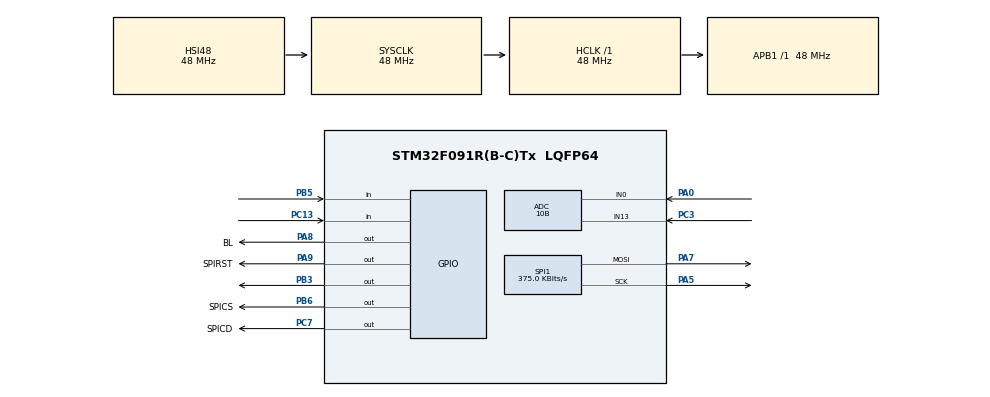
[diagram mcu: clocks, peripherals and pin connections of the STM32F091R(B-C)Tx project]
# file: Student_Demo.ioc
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ADC.ClockPrescaler=ADC_CLOCK_ASYNC_DIV1
ADC.ContinuousConvMode=DISABLE
ADC.Resolution=ADC_RESOLUTION_10B
Mcu.Family=STM32F0
Mcu.Name=STM32F091R(B-C)Tx
Mcu.Package=LQFP64
PA0.Signal=SharedAnalog_PA0
PA5.Mode=TX_Only_Simplex_Unidirect_Master
PA5.Signal=SPI1_SCK
PA7.Mode=TX_Only_Simplex_Unidirect_Master
PA7.Signal=SPI1_MOSI
PA8.GPIO_Label=BL
PA8.Signal=GPIO_Output
PA9.GPIO_Label=SPIRST
PA9.Signal=GPIO_Output
PB3.Signal=GPIO_Output
PB5.Signal=GPIO_Input
PB6.GPIO_Label=SPICS
PB6.Signal=GPIO_Output
PC13.Signal=GPIO_Input
PC14OSC32_IN.Mode=LSE-External-Oscillator
PC14OSC32_IN.Signal=RCC_OSC32_IN
PC15OSC32_OUT.Mode=LSE-External-Oscillator
PC15OSC32_OUT.Signal=RCC_OSC32_OUT
PC3.Mode=IN13
PC3.Signal=ADC_IN13
PC7.GPIO_Label=SPICD
PC7.PinState=GPIO_PIN_SET
PC7.Signal=GPIO_Output
PF0-OSC_IN.Mode=HSE-External-Oscillator
PF0-OSC_IN.Signal=RCC_OSC_IN
PF1-OSC_OUT.Mode=HSE-External-Oscillator
PF1-OSC_OUT.Signal=RCC_OSC_OUT
ProjectManager.HeapSize=0x200
ProjectManager.StackSize=0x400
ProjectManager.TargetToolchain=STM32CubeIDE
RCC.AHBFreq_Value=48000000
RCC.APB1Freq_Value=48000000
RCC.APB1TimFreq_Value=48000000
RCC.FLatency-AdvancedSettings=FLASH_LATENCY_1
RCC.HCLKFreq_Value=48000000
RCC.PLLDivider=RCC_PREDIV_DIV2
RCC.PLLMUL=RCC_PLL_MUL12
RCC.PLLSourceVirtual=RCC_PLLSOURCE_HSE
RCC.PREFETCH_ENABLE-AdvancedSettings=1
RCC.SYSCLKFreq_VALUE=48000000
RCC.SYSCLKSource=RCC_SYSCLKSOURCE_HSI48
SH.SharedAnalog_PA0.0=GPIO_Analog
SH.SharedAnalog_PA0.1=ADC_IN0,IN0
SPI1.BaudRatePrescaler=SPI_BAUDRATEPRESCALER_128
SPI1.CalculateBaudRate=375.0 KBits/s
SPI1.DataSize=SPI_DATASIZE_8BIT
SPI1.Direction=SPI_DIRECTION_2LINES
SPI1.Mode=SPI_MODE_MASTER
SPI1.VirtualType=VM_MASTER
TIM16.Period=10000
TIM16.Prescaler=4800-1
VP_ADC_TempSens_Input.Mode=IN-TempSens
VP_ADC_Vbat_Input.Mode=IN-Vbat
VP_TIM16_VS_ClockSourceINT.Mode=Enable_Timer
board=NUCLEO-F091RC

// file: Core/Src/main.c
/* USER CODE BEGIN Header */
/**
 ******************************************************************************
 * @file           : main.c
 * @brief          : Main program body
 ******************************************************************************
 * @attention
 *
 * Copyright (c) 2022 STMicroelectronics.
 * All rights reserved.
 *
 * This software is licensed under terms that can be found in the LICENSE file
 * in the root directory of this software component.
 * If no LICENSE file comes with this software, it is provided AS-IS.
 *
 ******************************************************************************
 */
/* USER CODE END Header */
#include "main.h"

/* USER CODE BEGIN Includes */
#include "OS.h"
#include "lcd_st7565_pinconf.h"
#include "lcd_st7565.h"
#include "font.h"

#define Avg_Slope .0025
#define V25 0.76
float val = 0.0;
double Temp = 0.0;
#define ItemiMeniu 6

/* USER CODE END Includes */

ADC_HandleTypeDef hadc;

SPI_HandleTypeDef hspi1;

TIM_HandleTypeDef htim16;

void SystemClock_Config(void);
static void MX_GPIO_Init(void);
static void MX_TIM16_Init(void);
static void MX_ADC_Init(void);
static void MX_SPI1_Init(void);
/* USER CODE BEGIN PFP */
void ADC_Select_CH0 (int rang);
void ADC_Select_CH13 (int rang);
void ADC_Disable_CH13(void);
void ADC_Disable_CH0(void);
void ADC_Disable_CHtemp(void);
void ADC_Select_CHTemp (int rang);
/* USER CODE END PFP */

/* USER CODE BEGIN 0 */
uint8_t ptData[] =
{ // 'j_b-removebg-1200x1200', 128x64px
		0x00, 0x00, 0x00, 0x00, 0x00, 0x00, 0x00, 0x00, 0x00, 0x00, 0x00, 0x00, 0x00, 0x00, 0x00, 0x00,
			0x00, 0x00, 0x00, 0x00, 0x00, 0x00, 0x00, 0x00, 0x00, 0x00, 0x00, 0x00, 0x00, 0x00, 0x00, 0x00,
			0x00, 0x00, 0x00, 0x00, 0x00, 0x00, 0x00, 0x00, 0x00, 0x00, 0x00, 0x00, 0x00, 0x00, 0x00, 0x00,
			0x00, 0x00, 0x00, 0x00, 0x00, 0x00, 0x00, 0x00, 0x00, 0x00, 0x00, 0x00, 0x00, 0x00, 0x00, 0x00,
			0x00, 0x00, 0x00, 0x00, 0x00, 0x00, 0x00, 0x00, 0x00, 0x00, 0x00, 0x00, 0x00, 0x00, 0x00, 0x00,
			0x00, 0x00, 0x00, 0x00, 0x00, 0x00, 0x00, 0x00, 0x00, 0x00, 0x00, 0x00, 0x00, 0x00, 0x00, 0x00,
			0x00, 0x00, 0x00, 0x00, 0x00, 0x00, 0x00, 0x00, 0x00, 0x80, 0xc0, 0xc0, 0xc0, 0xc0, 0xf0, 0xf0,
			0xf0, 0xf0, 0xf0, 0xf0, 0xf0, 0xf0, 0xc0, 0xc0, 0xc0, 0xc0, 0x80, 0x00, 0x00, 0x00, 0x00, 0x00,
			0x00, 0x00, 0x00, 0x00, 0x00, 0x00, 0x00, 0x00, 0x00, 0x00, 0x00, 0x00, 0x00, 0x00, 0x00, 0x00,
			0x00, 0x00, 0x00, 0x00, 0x00, 0x00, 0x00, 0x00, 0x00, 0x00, 0x00, 0x00, 0x00, 0x00, 0x00, 0x00,
			0x00, 0x00, 0x00, 0x00, 0x00, 0x00, 0x00, 0x00, 0x00, 0x00, 0x00, 0x00, 0x00, 0x00, 0x00, 0x00,
			0x00, 0x00, 0x00, 0x00, 0x00, 0x00, 0x00, 0x00, 0x00, 0x00, 0x00, 0x00, 0x00, 0x00, 0x00, 0x00,
			0x00, 0x00, 0x00, 0x00, 0x00, 0x00, 0x00, 0x00, 0x00, 0x00, 0x00, 0x00, 0x00, 0x00, 0x00, 0x00,
			0x00, 0x00, 0x00, 0x00, 0x00, 0x00, 0x00, 0x00, 0x00, 0x00, 0x00, 0x00, 0x00, 0x00, 0x00, 0x00,
			0x00, 0x00, 0x00, 0x00, 0x00, 0x00, 0x00, 0x00, 0x00, 0xff, 0x00, 0x00, 0x00, 0x00, 0x00, 0x00,
			0x00, 0x00, 0x00, 0x00, 0x00, 0x00, 0x00, 0x00, 0x00, 0x00, 0xff, 0x00, 0x00, 0x00, 0x00, 0x00,
			0x00, 0x00, 0x00, 0x00, 0x00, 0x00, 0x00, 0x00, 0x00, 0x00, 0x00, 0x00, 0x00, 0x00, 0x00, 0x00,
			0x00, 0x00, 0x00, 0x00, 0x00, 0x00, 0x00, 0x00, 0x00, 0x00, 0x00, 0x00, 0x00, 0x00, 0x00, 0x00,
			0x00, 0x00, 0x00, 0x00, 0x00, 0x00, 0x00, 0x00, 0x00, 0x00, 0x00, 0x00, 0x00, 0x00, 0x00, 0x00,
			0x00, 0x00, 0x00, 0x00, 0x00, 0x00, 0x00, 0x00, 0x00, 0x00, 0x00, 0x00, 0x00, 0x00, 0x00, 0x00,
			0x00, 0x00, 0x00, 0x00, 0x00, 0x00, 0x00, 0x00, 0x00, 0x00, 0x00, 0x00, 0x00, 0x00, 0x00, 0x00,
			0x00, 0x00, 0x00, 0x00, 0x00, 0x00, 0x00, 0x00, 0x00, 0x00, 0x00, 0x00, 0x00, 0x00, 0x00, 0x00,
			0x00, 0x00, 0x00, 0x00, 0x00, 0x00, 0x00, 0x00, 0x00, 0xff, 0x00, 0x00, 0x00, 0x00, 0x00, 0x00,
			0x00, 0x00, 0x00, 0x00, 0x00, 0x00, 0x00, 0x00, 0x00, 0x00, 0xff, 0x00, 0x00, 0x00, 0x00, 0x00,
			0x00, 0x00, 0x00, 0x00, 0x00, 0x00, 0x00, 0x00, 0x00, 0x00, 0x00, 0x00, 0x00, 0x00, 0x00, 0x00,
			0x00, 0x00, 0x00, 0x00, 0x00, 0x00, 0x00, 0x00, 0x00, 0x00, 0x00, 0x00, 0x00, 0x00, 0x00, 0x00,
			0x00, 0x00, 0x00, 0x00, 0x00, 0x00, 0x00, 0x00, 0x00, 0x00, 0x00, 0x00, 0x00, 0x00, 0x00, 0x00,
			0x00, 0x00, 0x00, 0x00, 0x00, 0x00, 0x00, 0x00, 0x00, 0x00, 0x00, 0x00, 0x00, 0x00, 0x00, 0x00,
			0x00, 0x00, 0x00, 0x00, 0x00, 0x00, 0x00, 0x00, 0x00, 0x00, 0x00, 0x00, 0x00, 0x00, 0x00, 0x00,
			0x00, 0x00, 0x00, 0x00, 0x00, 0x00, 0x00, 0x00, 0x00, 0x00, 0x00, 0x00, 0x00, 0x00, 0x00, 0x00,
			0x00, 0x00, 0x00, 0x00, 0x00, 0x00, 0x00, 0x00, 0x00, 0xff, 0x00, 0x00, 0x00, 0x00, 0x00, 0x00,
			0x00, 0x00, 0x00, 0x00, 0x00, 0x00, 0x00, 0x00, 0x00, 0x00, 0xff, 0x00, 0x00, 0x00, 0x00, 0x00,
			0x00, 0x00, 0x00, 0x00, 0x00, 0x00, 0x00, 0x00, 0x00, 0x00, 0x00, 0x00, 0x00, 0x00, 0x00, 0x00,
			0x00, 0x00, 0x00, 0x00, 0x00, 0x00, 0x00, 0x00, 0x00, 0x00, 0x00, 0x00, 0x00, 0x00, 0x00, 0x00,
			0x00, 0x00, 0x00, 0x00, 0x00, 0x00, 0x00, 0x00, 0x00, 0x00, 0x00, 0x00, 0x00, 0x00, 0x00, 0x00,
			0x00, 0x00, 0x00, 0x00, 0x00, 0x00, 0x00, 0x00, 0x00, 0x00, 0x00, 0x00, 0x00, 0x00, 0x00, 0x00,
			0x00, 0x00, 0x00, 0x00, 0x00, 0x00, 0x00, 0x00, 0x00, 0x00, 0x00, 0x00, 0x00, 0x00, 0x00, 0x00,
			0x00, 0x00, 0x00, 0x00, 0x00, 0x00, 0x00, 0x00, 0x00, 0x00, 0x00, 0x00, 0x00, 0x00, 0x00, 0x00,
			0x00, 0x00, 0x00, 0x00, 0x00, 0x00, 0x00, 0x00, 0x00, 0xff, 0x00, 0x00, 0x00, 0x00, 0x00, 0x00,
			0x00, 0x00, 0x00, 0x00, 0x00, 0x00, 0x00, 0x00, 0x00, 0x00, 0xff, 0x00, 0x00, 0x00, 0x00, 0x00,
			0x00, 0x00, 0x00, 0x00, 0x00, 0x00, 0x00, 0x00, 0x00, 0x00, 0x00, 0x00, 0x00, 0x00, 0x00, 0x00,
			0x00, 0x00, 0x00, 0x00, 0x00, 0x00, 0x00, 0x00, 0x00, 0x00, 0x00, 0x00, 0x00, 0x00, 0x00, 0x00,
			0x00, 0x00, 0x00, 0x00, 0x00, 0x00, 0x00, 0x00, 0x00, 0x00, 0x00, 0x00, 0x00, 0x00, 0x00, 0x00,
			0x00, 0x00, 0x00, 0x00, 0x00, 0x00, 0x00, 0x00, 0x00, 0x00, 0x00, 0x00, 0x00, 0x00, 0x00, 0x00,
			0x00, 0x00, 0x00, 0x00, 0x00, 0x00, 0x00, 0x00, 0x00, 0x00, 0x00, 0x00, 0x00, 0x00, 0x00, 0x00,
			0x00, 0x00, 0x00, 0x00, 0x00, 0x00, 0x00, 0x00, 0x00, 0x00, 0x00, 0x00, 0x00, 0x00, 0x00, 0x00,
			0x00, 0x00, 0x00, 0x00, 0x00, 0x00, 0x00, 0x00, 0x00, 0xff, 0x00, 0x00, 0x00, 0x00, 0x00, 0x00,
			0x00, 0x00, 0x00, 0x00, 0x00, 0x00, 0x00, 0x00, 0x00, 0x00, 0xff, 0x00, 0x00, 0x00, 0x00, 0x00,
			0x00, 0x00, 0x00, 0x00, 0x00, 0x00, 0x00, 0x00, 0x00, 0x00, 0x00, 0x00, 0x00, 0x00, 0x00, 0x00,
			0x00, 0x00, 0x00, 0x00, 0x00, 0x00, 0x00, 0x00, 0x00, 0x00, 0x00, 0x00, 0x00, 0x00, 0x00, 0x00,
			0x00, 0x00, 0x00, 0x00, 0x00, 0x00, 0x00, 0x00, 0x00, 0x00, 0x00, 0x00, 0x00, 0x00, 0x00, 0x00,
			0x00, 0x00, 0x00, 0x00, 0x00, 0x00, 0x00, 0x00, 0x00, 0x00, 0x00, 0x00, 0x00, 0x00, 0x00, 0x00,
			0x00, 0x00, 0x00, 0x00, 0x00, 0x00, 0x00, 0x00, 0x00, 0x00, 0x00, 0x00, 0x00, 0x00, 0x00, 0x00,
			0x00, 0x00, 0x00, 0x00, 0x00, 0x00, 0x00, 0x00, 0x00, 0x00, 0x00, 0x00, 0x00, 0x00, 0x00, 0x00,
			0x00, 0x00, 0x00, 0x00, 0x00, 0x00, 0x00, 0x00, 0x00, 0xff, 0x00, 0x00, 0x00, 0x00, 0x00, 0x00,
			0x00, 0x00, 0x00, 0x00, 0x00, 0x00, 0x00, 0x00, 0x00, 0x00, 0xff, 0x00, 0x00, 0x00, 0x00, 0x00,
			0x00, 0x00, 0x00, 0x00, 0x00, 0x00, 0x00, 0x00, 0x00, 0x00, 0x00, 0x00, 0x00, 0x00, 0x00, 0x00,
			0x00, 0x00, 0x00, 0x00, 0x00, 0x00, 0x00, 0x00, 0x00, 0x00, 0x00, 0x00, 0x00, 0x00, 0x00, 0x00,
			0x00, 0x00, 0x00, 0x00, 0x00, 0x00, 0x00, 0x00, 0x00, 0x00, 0x00, 0x00, 0x00, 0x00, 0x00, 0x00,
			0x00, 0x00, 0x00, 0x00, 0x00, 0x00, 0x00, 0x00, 0x00, 0x00, 0x00, 0x00, 0x00, 0x00, 0x00, 0x00,
			0x00, 0x00, 0x00, 0x00, 0x00, 0x00, 0x00, 0x00, 0x00, 0x00, 0x00, 0x00, 0x00, 0x00, 0x00, 0x00,
			0x00, 0x00, 0x00, 0x00, 0x00, 0x00, 0x00, 0x00, 0x00, 0x00, 0x00, 0x00, 0x00, 0x00, 0x00, 0x00,
			0x00, 0x00, 0x00, 0x00, 0x00, 0x00, 0x00, 0x00, 0x00, 0x07, 0x06, 0x0e, 0x0e, 0x0e, 0x0e, 0x0e,
			0x0e, 0x0e, 0x0e, 0x0e, 0x0e, 0x0e, 0x0e, 0x0e, 0x0e, 0x0e, 0x07, 0x00, 0x00, 0x00, 0x00, 0x00};

uint8_t ptData1[] =
{ // 'j_b-removebg-1200x1200', 128x64px
		0x00, 0x00, 0x00, 0x00, 0x00, 0x00, 0x00, 0x00, 0x00, 0x00, 0x00, 0x00, 0x00, 0x00, 0x00, 0x00,
		0x00, 0x00, 0x00, 0x00, 0x00, 0x00, 0x00, 0x00, 0x00, 0x00, 0x00, 0x00, 0x00, 0x00, 0x00, 0x00,
		0x00, 0x00, 0x00, 0x00, 0x00, 0x00, 0x00, 0x00, 0x00, 0x00, 0x00, 0x00, 0x00, 0x00, 0x00, 0x00,
		0x00, 0x00, 0x00, 0x00, 0x00, 0x00, 0x00, 0x00, 0x00, 0x00, 0x00, 0x00, 0x00, 0x00, 0x00, 0x00,
		0x00, 0x00, 0x00, 0x00, 0x00, 0x00, 0x00, 0x00, 0x00, 0x00, 0x00, 0x00, 0x00, 0x00, 0x00, 0x00,
		0x00, 0x00, 0x00, 0x00, 0x00, 0x00, 0x00, 0x00, 0x00, 0x00, 0x00, 0x00, 0x00, 0x00, 0x00, 0x00,
		0x00, 0x00, 0x00, 0x00, 0x00, 0x00, 0x00, 0x00, 0x00, 0x00, 0x80, 0xc0, 0xc0, 0xc0, 0xc0, 0xf0,
		0xf0, 0xf0, 0xf0, 0xf0, 0xf0, 0xf0, 0xf0, 0xc0, 0xc0, 0xc0, 0xc0, 0x80, 0x00, 0x00, 0x00, 0x00,
		0x00, 0x00, 0x00, 0x00, 0x00, 0x00, 0x00, 0x00, 0x00, 0x00, 0x00, 0x00, 0x00, 0x00, 0x00, 0x00,
		0x00, 0x00, 0x00, 0x00, 0x00, 0x00, 0x00, 0x00, 0x00, 0x00, 0x00, 0x00, 0x00, 0x00, 0x00, 0x00,
		0x00, 0x00, 0x00, 0x00, 0x00, 0x00, 0x00, 0x00, 0x00, 0x00, 0x00, 0x00, 0x00, 0x00, 0x00, 0x00,
		0x00, 0x00, 0x00, 0x00, 0x00, 0x00, 0x00, 0x00, 0x00, 0x00, 0x00, 0x00, 0x00, 0x00, 0x00, 0x00,
		0x00, 0x00, 0x00, 0x00, 0x00, 0x00, 0x00, 0x00, 0x00, 0x00, 0x00, 0x00, 0x00, 0x00, 0x00, 0x00,
		0x00, 0x00, 0x00, 0x00, 0x00, 0x00, 0x00, 0x00, 0x00, 0x00, 0x00, 0x00, 0x00, 0x00, 0x00, 0x00,
		0x00, 0x00, 0x00, 0x00, 0x00, 0x00, 0x00, 0x00, 0x00, 0x00, 0xff, 0x00, 0x00, 0x00, 0x00, 0x00,
		0x00, 0x00, 0x00, 0x00, 0x00, 0x00, 0x00, 0x00, 0x00, 0x00, 0x00, 0xff, 0x00, 0x00, 0x00, 0x00,
		0x00, 0x00, 0x00, 0x00, 0x00, 0x00, 0x00, 0x00, 0x00, 0x00, 0x00, 0x00, 0x00, 0x00, 0x00, 0x00,
		0x00, 0x00, 0x00, 0x00, 0x00, 0x00, 0x00, 0x00, 0x00, 0x00, 0x00, 0x00, 0x00, 0x00, 0x00, 0x00,
		0x00, 0x00, 0x00, 0x00, 0x00, 0x00, 0x00, 0x00, 0x00, 0x00, 0x00, 0x00, 0x00, 0x00, 0x00, 0x00,
		0x00, 0x00, 0x00, 0x00, 0x00, 0x00, 0x00, 0x00, 0x00, 0x00, 0x00, 0x00, 0x00, 0x00, 0x00, 0x00,
		0x00, 0x00, 0x00, 0x00, 0x00, 0x00, 0x00, 0x00, 0x00, 0x00, 0x00, 0x00, 0x00, 0x00, 0x00, 0x00,
		0x00, 0x00, 0x00, 0x00, 0x00, 0x00, 0x00, 0x00, 0x00, 0x00, 0x00, 0x00, 0x00, 0x00, 0x00, 0x00,
		0x00, 0x00, 0x00, 0x00, 0x00, 0x00, 0x00, 0x00, 0x00, 0x00, 0xff, 0x00, 0x00, 0x00, 0x00, 0x00,
		0x00, 0x00, 0x00, 0x00, 0x00, 0x00, 0x00, 0x00, 0x00, 0x00, 0x00, 0xff, 0x00, 0x00, 0x00, 0x00,
		0x00, 0x00, 0x00, 0x00, 0x00, 0x00, 0x00, 0x00, 0x00, 0x00, 0x00, 0x00, 0x00, 0x00, 0x00, 0x00,
		0x00, 0x00, 0x00, 0x00, 0x00, 0x00, 0x00, 0x00, 0x00, 0x00, 0x00, 0x00, 0x00, 0x00, 0x00, 0x00,
		0x00, 0x00, 0x00, 0x00, 0x00, 0x00, 0x00, 0x00, 0x00, 0x00, 0x00, 0x00, 0x00, 0x00, 0x00, 0x00,
		0x00, 0x00, 0x00, 0x00, 0x00, 0x00, 0x00, 0x00, 0x00, 0x00, 0x00, 0x00, 0x00, 0x00, 0x00, 0x00,
		0x00, 0x00, 0x00, 0x00, 0x00, 0x00, 0x00, 0x00, 0x00, 0x00, 0x00, 0x00, 0x00, 0x00, 0x00, 0x00,
		0x00, 0x00, 0x00, 0x00, 0x00, 0x00, 0x00, 0x00, 0x00, 0x00, 0x00, 0x00, 0x00, 0x00, 0x00, 0x00,
		0x00, 0x00, 0x00, 0x00, 0x00, 0x00, 0x00, 0x00, 0x00, 0x00, 0xff, 0x00, 0x00, 0x00, 0x00, 0x00,
		0x00, 0x00, 0x00, 0x00, 0x00, 0x00, 0x00, 0x00, 0x00, 0x00, 0x00, 0xff, 0x00, 0x00, 0x00, 0x00,
		0x00, 0x00, 0x00, 0x00, 0x00, 0x00, 0x00, 0x00, 0x00, 0x00, 0x00, 0x00, 0x00, 0x00, 0x00, 0x00,
		0x00, 0x00, 0x00, 0x00, 0x00, 0x00, 0x00, 0x00, 0x00, 0x00, 0x00, 0x00, 0x00, 0x00, 0x00, 0x00,
		0x00, 0x00, 0x00, 0x00, 0x00, 0x00, 0x00, 0x00, 0x00, 0x00, 0x00, 0x00, 0x00, 0x00, 0x00, 0x00,
		0x00, 0x00, 0x00, 0x00, 0x00, 0x00, 0x00, 0x00, 0x00, 0x00, 0x00, 0x00, 0x00, 0x00, 0x00, 0x00,
		0x00, 0x00, 0x00, 0x00, 0x00, 0x00, 0x00, 0x00, 0x00, 0x00, 0x00, 0x00, 0x00, 0x00, 0x00, 0x00,
		0x00, 0x00, 0x00, 0x00, 0x00, 0x00, 0x00, 0x00, 0x00, 0x00, 0x00, 0x00, 0x00, 0x00, 0x00, 0x00,
		0x00, 0x00, 0x00, 0x00, 0x00, 0x00, 0x00, 0x00, 0x00, 0x00, 0xff, 0x00, 0x00, 0x00, 0x00, 0x00,
		0x00, 0x00, 0x00, 0x00, 0x00, 0x00, 0x00, 0x00, 0x00, 0x00, 0x00, 0xff, 0x00, 0x00, 0x00, 0x00,
		0x00, 0x00, 0x00, 0x00, 0x00, 0x00, 0x00, 0x00, 0x00, 0x00, 0x00, 0x00, 0x00, 0x00, 0x00, 0x00,
		0x00, 0x00, 0x00, 0x00, 0x00, 0x00, 0x00, 0x00, 0x00, 0x00, 0x00, 0x00, 0x00, 0x00, 0x00, 0x00,
		0x00, 0x00, 0x00, 0x00, 0x00, 0x00, 0x00, 0x00, 0x00, 0x00, 0x00, 0x00, 0x00, 0x00, 0x00, 0x00,
		0x00, 0x00, 0x00, 0x00, 0x00, 0x00, 0x00, 0x00, 0x00, 0x00, 0x00, 0x00, 0x00, 0x00, 0x00, 0x00,
		0x00, 0x00, 0x00, 0x00, 0x00, 0x00, 0x00, 0x00, 0x00, 0x00, 0x00, 0x00, 0x00, 0x00, 0x00, 0x00,
		0x00, 0x00, 0x00, 0x00, 0x00, 0x00, 0x00, 0x00, 0x00, 0x00, 0x00, 0x00, 0x00, 0x00, 0x00, 0x00,
		0x00, 0x00, 0x00, 0x00, 0x00, 0x00, 0x00, 0x00, 0x00, 0x00, 0xff, 0x00, 0x00, 0x00, 0x00, 0x00,
		0x00, 0x00, 0x00, 0x00, 0x00, 0x00, 0x00, 0x00, 0x00, 0x00, 0x00, 0xff, 0x00, 0x00, 0x00, 0x00,
		0x00, 0x00, 0x00, 0x00, 0x00, 0x00, 0x00, 0x00, 0x00, 0x00, 0x00, 0x00, 0x00, 0x00, 0x00, 0x00,
		0x00, 0x00, 0x00, 0x00, 0x00, 0x00, 0x00, 0x00, 0x00, 0x00, 0x00, 0x00, 0x00, 0x00, 0x00, 0x00,
		0x00, 0x00, 0x00, 0x00, 0x00, 0x00, 0x00, 0x00, 0x00, 0x00, 0x00, 0x00, 0x00, 0x00, 0x00, 0x00,
		0x00, 0x00, 0x00, 0x00, 0x00, 0x00, 0x00, 0x00, 0x00, 0x00, 0x00, 0x00, 0x00, 0x00, 0x00, 0x00,
		0x00, 0x00, 0x00, 0x00, 0x00, 0x00, 0x00, 0x00, 0x00, 0x00, 0x00, 0x00, 0x00, 0x00, 0x00, 0x00,
		0x00, 0x00, 0x00, 0x00, 0x00, 0x00, 0x00, 0x00, 0x00, 0x00, 0x00, 0x00, 0x00, 0x00, 0x00, 0x00,
		0x00, 0x00, 0x00, 0x00, 0x00, 0x00, 0x00, 0x00, 0x00, 0x00, 0xff, 0x00, 0x7f, 0x7f, 0x7f, 0x7f,
		0x7f, 0x7f, 0x7f, 0x7f, 0x7f, 0x7f, 0x7f, 0x7f, 0x7f, 0x00, 0x00, 0xff, 0x00, 0x00, 0x00, 0x00,
		0x00, 0x00, 0x00, 0x00, 0x00, 0x00, 0x00, 0x00, 0x00, 0x00, 0x00, 0x00, 0x00, 0x00, 0x00, 0x00,
		0x00, 0x00, 0x00, 0x00, 0x00, 0x00, 0x00, 0x00, 0x00, 0x00, 0x00, 0x00, 0x00, 0x00, 0x00, 0x00,
		0x00, 0x00, 0x00, 0x00, 0x00, 0x00, 0x00, 0x00, 0x00, 0x00, 0x00, 0x00, 0x00, 0x00, 0x00, 0x00,
		0x00, 0x00, 0x00, 0x00, 0x00, 0x00, 0x00, 0x00, 0x00, 0x00, 0x00, 0x00, 0x00, 0x00, 0x00, 0x00,
		0x00, 0x00, 0x00, 0x00, 0x00, 0x00, 0x00, 0x00, 0x00, 0x00, 0x00, 0x00, 0x00, 0x00, 0x00, 0x00,
		0x00, 0x00, 0x00, 0x00, 0x00, 0x00, 0x00, 0x00, 0x00, 0x00, 0x00, 0x00, 0x00, 0x00, 0x00, 0x00,
		0x00, 0x00, 0x00, 0x00, 0x00, 0x00, 0x00, 0x00, 0x00, 0x00, 0x07, 0x0e, 0x0c, 0x0c, 0x0c, 0x0c,
		0x0c, 0x0c, 0x0c, 0x0c, 0x0c, 0x0c, 0x0c, 0x0c, 0x0c, 0x0c, 0x0e, 0x07, 0x00, 0x00, 0x00, 0x00};

uint8_t ptData2[] =
{ // 'j_b-removebg-1200x1200', 128x64px
		0x00, 0x00, 0x00, 0x00, 0x00, 0x00, 0x00, 0x00, 0x00, 0x00, 0x00, 0x00, 0x00, 0x00, 0x00, 0x00,
			0x00, 0x00, 0x00, 0x00, 0x00, 0x00, 0x00, 0x00, 0x00, 0x00, 0x00, 0x00, 0x00, 0x00, 0x00, 0x00,
			0x00, 0x00, 0x00, 0x00, 0x00, 0x00, 0x00, 0x00, 0x00, 0x00, 0x00, 0x00, 0x00, 0x00, 0x00, 0x00,
			0x00, 0x00, 0x00, 0x00, 0x00, 0x00, 0x00, 0x00, 0x00, 0x00, 0x00, 0x00, 0x00, 0x00, 0x00, 0x00,
			0x00, 0x00, 0x00, 0x00, 0x00, 0x00, 0x00, 0x00, 0x00, 0x00, 0x00, 0x00, 0x00, 0x00, 0x00, 0x00,
			0x00, 0x00, 0x00, 0x00, 0x00, 0x00, 0x00, 0x00, 0x00, 0x00, 0x00, 0x00, 0x00, 0x00, 0x00, 0x00,
			0x00, 0x00, 0x00, 0x00, 0x00, 0x00, 0x00, 0x00, 0x00, 0x00, 0x00, 0xc0, 0x60, 0x60, 0x60, 0x60,
			0x70, 0x70, 0x70, 0x70, 0x70, 0x70, 0x70, 0x70, 0x60, 0x60, 0x60, 0xe0, 0xc0, 0x00, 0x00, 0x00,
			0x00, 0x00, 0x00, 0x00, 0x00, 0x00, 0x00, 0x00, 0x00, 0x00, 0x00, 0x00, 0x00, 0x00, 0x00, 0x00,
			0x00, 0x00, 0x00, 0x00, 0x00, 0x00, 0x00, 0x00, 0x00, 0x00, 0x00, 0x00, 0x00, 0x00, 0x00, 0x00,
			0x00, 0x00, 0x00, 0x00, 0x00, 0x00, 0x00, 0x00, 0x00, 0x00, 0x00, 0x00, 0x00, 0x00, 0x00, 0x00,
			0x00, 0x00, 0x00, 0x00, 0x00, 0x00, 0x00, 0x00, 0x00, 0x00, 0x00, 0x00, 0x00, 0x00, 0x00, 0x00,
			0x00, 0x00, 0x00, 0x00, 0x00, 0x00, 0x00, 0x00, 0x00, 0x00, 0x00, 0x00, 0x00, 0x00, 0x00, 0x00,
			0x00, 0x00, 0x00, 0x00, 0x00, 0x00, 0x00, 0x00, 0x00, 0x00, 0x00, 0x00, 0x00, 0x00, 0x00, 0x00,
			0x00, 0x00, 0x00, 0x00, 0x00, 0x00, 0x00, 0x00, 0x00, 0x00, 0xff, 0xff, 0x00, 0x00, 0x00, 0x00,
			0x00, 0x00, 0x00, 0x00, 0x00, 0x00, 0x00, 0x00, 0x00, 0x00, 0x00, 0x00, 0xff, 0x00, 0x00, 0x00,
			0x00, 0x00, 0x00, 0x00, 0x00, 0x00, 0x00, 0x00, 0x00, 0x00, 0x00, 0x00, 0x00, 0x00, 0x00, 0x00,
			0x00, 0x00, 0x00, 0x00, 0x00, 0x00, 0x00, 0x00, 0x00, 0x00, 0x00, 0x00, 0x00, 0x00, 0x00, 0x00,
			0x00, 0x00, 0x00, 0x00, 0x00, 0x00, 0x00, 0x00, 0x00, 0x00, 0x00, 0x00, 0x00, 0x00, 0x00, 0x00,
			0x00, 0x00, 0x00, 0x00, 0x00, 0x00, 0x00, 0x00, 0x00, 0x00, 0x00, 0x00, 0x00, 0x00, 0x00, 0x00,
			0x00, 0x00, 0x00, 0x00, 0x00, 0x00, 0x00, 0x00, 0x00, 0x00, 0x00, 0x00, 0x00, 0x00, 0x00, 0x00,
			0x00, 0x00, 0x00, 0x00, 0x00, 0x00, 0x00, 0x00, 0x00, 0x00, 0x00, 0x00, 0x00, 0x00, 0x00, 0x00,
			0x00, 0x00, 0x00, 0x00, 0x00, 0x00, 0x00, 0x00, 0x00, 0x00, 0xff, 0xff, 0x00, 0x00, 0x00, 0x00,
			0x00, 0x00, 0x00, 0x00, 0x00, 0x00, 0x00, 0x00, 0x00, 0x00, 0x00, 0x00, 0xff, 0x00, 0x00, 0x00,
			0x00, 0x00, 0x00, 0x00, 0x00, 0x00, 0x00, 0x00, 0x00, 0x00, 0x00, 0x00, 0x00, 0x00, 0x00, 0x00,
			0x00, 0x00, 0x00, 0x00, 0x00, 0x00, 0x00, 0x00, 0x00, 0x00, 0x00, 0x00, 0x00, 0x00, 0x00, 0x00,
			0x00, 0x00, 0x00, 0x00, 0x00, 0x00, 0x00, 0x00, 0x00, 0x00, 0x00, 0x00, 0x00, 0x00, 0x00, 0x00,
			0x00, 0x00, 0x00, 0x00, 0x00, 0x00, 0x00, 0x00, 0x00, 0x00, 0x00, 0x00, 0x00, 0x00, 0x00, 0x00,
			0x00, 0x00, 0x00, 0x00, 0x00, 0x00, 0x00, 0x00, 0x00, 0x00, 0x00, 0x00, 0x00, 0x00, 0x00, 0x00,
			0x00, 0x00, 0x00, 0x00, 0x00, 0x00, 0x00, 0x00, 0x00, 0x00, 0x00, 0x00, 0x00, 0x00, 0x00, 0x00,
			0x00, 0x00, 0x00, 0x00, 0x00, 0x00, 0x00, 0x00, 0x00, 0x00, 0xff, 0xff, 0x00, 0x00, 0x00, 0x00,
			0x00, 0x00, 0x00, 0x00, 0x00, 0x00, 0x00, 0x00, 0x00, 0x00, 0x00, 0x00, 0xff, 0x00, 0x00, 0x00,
			0x00, 0x00, 0x00, 0x00, 0x00, 0x00, 0x00, 0x00, 0x00, 0x00, 0x00, 0x00, 0x00, 0x00, 0x00, 0x00,
			0x00, 0x00, 0x00, 0x00, 0x00, 0x00, 0x00, 0x00, 0x00, 0x00, 0x00, 0x00, 0x00, 0x00, 0x00, 0x00,
			0x00, 0x00, 0x00, 0x00, 0x00, 0x00, 0x00, 0x00, 0x00, 0x00, 0x00, 0x00, 0x00, 0x00, 0x00, 0x00,
			0x00, 0x00, 0x00, 0x00, 0x00, 0x00, 0x00, 0x00, 0x00, 0x00, 0x00, 0x00, 0x00, 0x00, 0x00, 0x00,
			0x00, 0x00, 0x00, 0x00, 0x00, 0x00, 0x00, 0x00, 0x00, 0x00, 0x00, 0x00, 0x00, 0x00, 0x00, 0x00,
			0x00, 0x00, 0x00, 0x00, 0x00, 0x00, 0x00, 0x00, 0x00, 0x00, 0x00, 0x00, 0x00, 0x00, 0x00, 0x00,
			0x00, 0x00, 0x00, 0x00, 0x00, 0x00, 0x00, 0x00, 0x00, 0x00, 0xff, 0xff, 0x00, 0xc0, 0xc0, 0xc0,
			0xc0, 0xc0, 0xc0, 0xc0, 0xc0, 0xc0, 0xc0, 0xc0, 0xc0, 0xc0, 0x00, 0x00, 0xff, 0x00, 0x00, 0x00,
			0x00, 0x00, 0x00, 0x00, 0x00, 0x00, 0x00, 0x00, 0x00, 0x00, 0x00, 0x00, 0x00, 0x00, 0x00, 0x00,
			0x00, 0x00, 0x00, 0x00, 0x00, 0x00, 0x00, 0x00, 0x00, 0x00, 0x00, 0x00, 0x00, 0x00, 0x00, 0x00,
			0x00, 0x00, 0x00, 0x00, 0x00, 0x00, 0x00, 0x00, 0x00, 0x00, 0x00, 0x00, 0x00, 0x00, 0x00, 0x00,
			0x00, 0x00, 0x00, 0x00, 0x00, 0x00, 0x00, 0x00, 0x00, 0x00, 0x00, 0x00, 0x00, 0x00, 0x00, 0x00,
			0x00, 0x00, 0x00, 0x00, 0x00, 0x00, 0x00, 0x00, 0x00, 0x00, 0x00, 0x00, 0x00, 0x00, 0x00, 0x00,
			0x00, 0x00, 0x00, 0x00, 0x00, 0x00, 0x00, 0x00, 0x00, 0x00, 0x00, 0x00, 0x00, 0x00, 0x00, 0x00,
			0x00, 0x00, 0x00, 0x00, 0x00, 0x00, 0x00, 0x00, 0x00, 0x00, 0xff, 0xff, 0x00, 0x1f, 0x1f, 0x1f,
			0x1f, 0x1f, 0x1f, 0x1f, 0x1f, 0x1f, 0x1f, 0x1f, 0x1f, 0x1f, 0x00, 0x00, 0xff, 0x00, 0x00, 0x00,
			0x00, 0x00, 0x00, 0x00, 0x00, 0x00, 0x00, 0x00, 0x00, 0x00, 0x00, 0x00, 0x00, 0x00, 0x00, 0x00,
			0x00, 0x00, 0x00, 0x00, 0x00, 0x00, 0x00, 0x00, 0x00, 0x00, 0x00, 0x00, 0x00, 0x00, 0x00, 0x00,
			0x00, 0x00, 0x00, 0x00, 0x00, 0x00, 0x00, 0x00, 0x00, 0x00, 0x00, 0x00, 0x00, 0x00, 0x00, 0x00,
			0x00, 0x00, 0x00, 0x00, 0x00, 0x00, 0x00, 0x00, 0x00, 0x00, 0x00, 0x00, 0x00, 0x00, 0x00, 0x00,
			0x00, 0x00, 0x00, 0x00, 0x00, 0x00, 0x00, 0x00, 0x00, 0x00, 0x00, 0x00, 0x00, 0x00, 0x00, 0x00,
			0x00, 0x00, 0x00, 0x00, 0x00, 0x00, 0x00, 0x00, 0x00, 0x00, 0x00, 0x00, 0x00, 0x00, 0x00, 0x00,
			0x00, 0x00, 0x00, 0x00, 0x00, 0x00, 0x00, 0x00, 0x00, 0x00, 0xff, 0xff, 0x00, 0x3f, 0x3f, 0x3f,
			0x3f, 0x3f, 0x3f, 0x3f, 0x3f, 0x3f, 0x3f, 0x3f, 0x3f, 0x3f, 0x00, 0x00, 0xff, 0x00, 0x00, 0x00,
			0x00, 0x00, 0x00, 0x00, 0x00, 0x00, 0x00, 0x00, 0x00, 0x00, 0x00, 0x00, 0x00, 0x00, 0x00, 0x00,
			0x00, 0x00, 0x00, 0x00, 0x00, 0x00, 0x00, 0x00, 0x00, 0x00, 0x00, 0x00, 0x00, 0x00, 0x00, 0x00,
			0x00, 0x00, 0x00, 0x00, 0x00, 0x00, 0x00, 0x00, 0x00, 0x00, 0x00, 0x00, 0x00, 0x00, 0x00, 0x00,
			0x00, 0x00, 0x00, 0x00, 0x00, 0x00, 0x00, 0x00, 0x00, 0x00, 0x00, 0x00, 0x00, 0x00, 0x00, 0x00,
			0x00, 0x00, 0x00, 0x00, 0x00, 0x00, 0x00, 0x00, 0x00, 0x00, 0x00, 0x00, 0x00, 0x00, 0x00, 0x00,
			0x00, 0x00, 0x00, 0x00, 0x00, 0x00, 0x00, 0x00, 0x00, 0x00, 0x00, 0x00, 0x00, 0x00, 0x00, 0x00,
			0x00, 0x00, 0x00, 0x00, 0x00, 0x00, 0x00, 0x00, 0x00, 0x00, 0x00, 0x03, 0x06, 0x06, 0x06, 0x06,
			0x06, 0x06, 0x06, 0x06, 0x06, 0x06, 0x06, 0x06, 0x06, 0x06, 0x06, 0x07, 0x03, 0x00, 0x00, 0x00};

uint8_t ptData3[] =
{ // 'j_b-removebg-1200x1200', 128x64px
		0x00, 0x00, 0x00, 0x00, 0x00, 0x00, 0x00, 0x00, 0x00, 0x00, 0x00, 0x00, 0x00, 0x00, 0x00, 0x00,
		0x00, 0x00, 0x00, 0x00, 0x00, 0x00, 0x00, 0x00, 0x00, 0x00, 0x00, 0x00, 0x00, 0x00, 0x00, 0x00,
		0x00, 0x00, 0x00, 0x00, 0x00, 0x00, 0x00, 0x00, 0x00, 0x00, 0x00, 0x00, 0x00, 0x00, 0x00, 0x00,
		0x00, 0x00, 0x00, 0x00, 0x00, 0x00, 0x00, 0x00, 0x00, 0x00, 0x00, 0x00, 0x00, 0x00, 0x00, 0x00,
		0x00, 0x00, 0x00, 0x00, 0x00, 0x00, 0x00, 0x00, 0x00, 0x00, 0x00, 0x00, 0x00, 0x00, 0x00, 0x00,
		0x00, 0x00, 0x00, 0x00, 0x00, 0x00, 0x00, 0x00, 0x00, 0x00, 0x00, 0x00, 0x00, 0x00, 0x00, 0x00,
		0x00, 0x00, 0x00, 0x00, 0x00, 0x00, 0x00, 0x00, 0x00, 0x00, 0x00, 0x00, 0xc0, 0x70, 0x30, 0x30,
		0x30, 0x38, 0x3c, 0x3c, 0x3c, 0x3c, 0x3c, 0x3c, 0x3c, 0x30, 0x30, 0x30, 0x30, 0xf0, 0xc0, 0x00,
		0x00, 0x00, 0x00, 0x00, 0x00, 0x00, 0x00, 0x00, 0x00, 0x00, 0x00, 0x00, 0x00, 0x00, 0x00, 0x00,
		0x00, 0x00, 0x00, 0x00, 0x00, 0x00, 0x00, 0x00, 0x00, 0x00, 0x00, 0x00, 0x00, 0x00, 0x00, 0x00,
		0x00, 0x00, 0x00, 0x00, 0x00, 0x00, 0x00, 0x00, 0x00, 0x00, 0x00, 0x00, 0x00, 0x00, 0x00, 0x00,
		0x00, 0x00, 0x00, 0x00, 0x00, 0x00, 0x00, 0x00, 0x00, 0x00, 0x00, 0x00, 0x00, 0x00, 0x00, 0x00,
		0x00, 0x00, 0x00, 0x00, 0x00, 0x00, 0x00, 0x00, 0x00, 0x00, 0x00, 0x00, 0x00, 0x00, 0x00, 0x00,
		0x00, 0x00, 0x00, 0x00, 0x00, 0x00, 0x00, 0x00, 0x00, 0x00, 0x00, 0x00, 0x00, 0x00, 0x00, 0x00,
		0x00, 0x00, 0x00, 0x00, 0x00, 0x00, 0x00, 0x00, 0x00, 0x00, 0x00, 0x00, 0xff, 0x00, 0x00, 0x00,
		0x00, 0x00, 0x00, 0x00, 0x00, 0x00, 0x00, 0x00, 0x00, 0x00, 0x00, 0x00, 0x00, 0xff, 0xff, 0x00,
		0x00, 0x00, 0x00, 0x00, 0x00, 0x00, 0x00, 0x00, 0x00, 0x00, 0x00, 0x00, 0x00, 0x00, 0x00, 0x00,
		0x00, 0x00, 0x00, 0x00, 0x00, 0x00, 0x00, 0x00, 0x00, 0x00, 0x00, 0x00, 0x00, 0x00, 0x00, 0x00,
		0x00, 0x00, 0x00, 0x00, 0x00, 0x00, 0x00, 0x00, 0x00, 0x00, 0x00, 0x00, 0x00, 0x00, 0x00, 0x00,
		0x00, 0x00, 0x00, 0x00, 0x00, 0x00, 0x00, 0x00, 0x00, 0x00, 0x00, 0x00, 0x00, 0x00, 0x00, 0x00,
		0x00, 0x00, 0x00, 0x00, 0x00, 0x00, 0x00, 0x00, 0x00, 0x00, 0x00, 0x00, 0x00, 0x00, 0x00, 0x00,
		0x00, 0x00, 0x00, 0x00, 0x00, 0x00, 0x00, 0x00, 0x00, 0x00, 0x00, 0x00, 0x00, 0x00, 0x00, 0x00,
		0x00, 0x00, 0x00, 0x00, 0x00, 0x00, 0x00, 0x00, 0x00, 0x00, 0x00, 0x00, 0xff, 0x00, 0x00, 0x00,
		0x00, 0x00, 0x00, 0x00, 0x00, 0x00, 0x00, 0x00, 0x00, 0x00, 0x00, 0x00, 0x00, 0xff, 0xff, 0x00,
		0x00, 0x00, 0x00, 0x00, 0x00, 0x00, 0x00, 0x00, 0x00, 0x00, 0x00, 0x00, 0x00, 0x00, 0x00, 0x00,
		0x00, 0x00, 0x00, 0x00, 0x00, 0x00, 0x00, 0x00, 0x00, 0x00, 0x00, 0x00, 0x00, 0x00, 0x00, 0x00,
		0x00, 0x00, 0x00, 0x00, 0x00, 0x00, 0x00, 0x00, 0x00, 0x00, 0x00, 0x00, 0x00, 0x00, 0x00, 0x00,
		0x00, 0x00, 0x00, 0x00, 0x00, 0x00, 0x00, 0x00, 0x00, 0x00, 0x00, 0x00, 0x00, 0x00, 0x00, 0x00,
		0x00, 0x00, 0x00, 0x00, 0x00, 0x00, 0x00, 0x00, 0x00, 0x00, 0x00, 0x00, 0x00, 0x00, 0x00, 0x00,
		0x00, 0x00, 0x00, 0x00, 0x00, 0x00, 0x00, 0x00, 0x00, 0x00, 0x00, 0x00, 0x00, 0x00, 0x00, 0x00,
		0x00, 0x00, 0x00, 0x00, 0x00, 0x00, 0x00, 0x00, 0x00, 0x00, 0x00, 0x00, 0xff, 0x00, 0x00, 0xf0,
		0xf0, 0xf0, 0xf0, 0xf0, 0xf0, 0xf0, 0xf0, 0xf0, 0xf0, 0xf0, 0xf0, 0xf0, 0x00, 0xff, 0xff, 0x00,
		0x00, 0x00, 0x00, 0x00, 0x00, 0x00, 0x00, 0x00, 0x00, 0x00, 0x00, 0x00, 0x00, 0x00, 0x00, 0x00,
		0x00, 0x00, 0x00, 0x00, 0x00, 0x00, 0x00, 0x00, 0x00, 0x00, 0x00, 0x00, 0x00, 0x00, 0x00, 0x00,
		0x00, 0x00, 0x00, 0x00, 0x00, 0x00, 0x00, 0x00, 0x00, 0x00, 0x00, 0x00, 0x00, 0x00, 0x00, 0x00,
		0x00, 0x00, 0x00, 0x00, 0x00, 0x00, 0x00, 0x00, 0x00, 0x00, 0x00, 0x00, 0x00, 0x00, 0x00, 0x00,
		0x00, 0x00, 0x00, 0x00, 0x00, 0x00, 0x00, 0x00, 0x00, 0x00, 0x00, 0x00, 0x00, 0x00, 0x00, 0x00,
		0x00, 0x00, 0x00, 0x00, 0x00, 0x00, 0x00, 0x00, 0x00, 0x00, 0x00, 0x00, 0x00, 0x00, 0x00, 0x00,
		0x00, 0x00, 0x00, 0x00, 0x00, 0x00, 0x00, 0x00, 0x00, 0x00, 0x00, 0x00, 0xff, 0x00, 0x00, 0xe3,
		0xe3, 0xe3, 0xe3, 0xe3, 0xe3, 0xe3, 0xe3, 0xe3, 0xe3, 0xe3, 0xe3, 0xe3, 0x00, 0xff, 0xff, 0x00,
		0x00, 0x00, 0x00, 0x00, 0x00, 0x00, 0x00, 0x00, 0x00, 0x00, 0x00, 0x00, 0x00, 0x00, 0x00, 0x00,
		0x00, 0x00, 0x00, 0x00, 0x00, 0x00, 0x00, 0x00, 0x00, 0x00, 0x00, 0x00, 0x00, 0x00, 0x00, 0x00,
		0x00, 0x00, 0x00, 0x00, 0x00, 0x00, 0x00, 0x00, 0x00, 0x00, 0x00, 0x00, 0x00, 0x00, 0x00, 0x00,
		0x00, 0x00, 0x00, 0x00, 0x00, 0x00, 0x00, 0x00, 0x00, 0x00, 0x00, 0x00, 0x00, 0x00, 0x00, 0x00,
		0x00, 0x00, 0x00, 0x00, 0x00, 0x00, 0x00, 0x00, 0x00, 0x00, 0x00, 0x00, 0x00, 0x00, 0x00, 0x00,
		0x00, 0x00, 0x00, 0x00, 0x00, 0x00, 0x00, 0x00, 0x00, 0x00, 0x00, 0x00, 0x00, 0x00, 0x00, 0x00,
		0x00, 0x00, 0x00, 0x00, 0x00, 0x00, 0x00, 0x00, 0x00, 0x00, 0x00, 0x00, 0xff, 0x00, 0x00, 0x8f,
		0x8f, 0x8f, 0x8f, 0x8f, 0x8f, 0x8f, 0x8f, 0x8f, 0x8f, 0x8f, 0x8f, 0x8f, 0x00, 0xff, 0xff, 0x00,
		0x00, 0x00, 0x00, 0x00, 0x00, 0x00, 0x00, 0x00, 0x00, 0x00, 0x00, 0x00, 0x00, 0x00, 0x00, 0x00,
		0x00, 0x00, 0x00, 0x00, 0x00, 0x00, 0x00, 0x00, 0x00, 0x00, 0x00, 0x00, 0x00, 0x00, 0x00, 0x00,
		0x00, 0x00, 0x00, 0x00, 0x00, 0x00, 0x00, 0x00, 0x00, 0x00, 0x00, 0x00, 0x00, 0x00, 0x00, 0x00,
		0x00, 0x00, 0x00, 0x00, 0x00, 0x00, 0x00, 0x00, 0x00, 0x00, 0x00, 0x00, 0x00, 0x00, 0x00, 0x00,
		0x00, 0x00, 0x00, 0x00, 0x00, 0x00, 0x00, 0x00, 0x00, 0x00, 0x00, 0x00, 0x00, 0x00, 0x00, 0x00,
		0x00, 0x00, 0x00, 0x00, 0x00, 0x00, 0x00, 0x00, 0x00, 0x00, 0x00, 0x00, 0x00, 0x00, 0x00, 0x00,
		0x00, 0x00, 0x00, 0x00, 0x00, 0x00, 0x00, 0x00, 0x00, 0x00, 0x00, 0x00, 0xff, 0x80, 0x00, 0x1f,
		0x1f, 0x1f, 0x1f, 0x1f, 0x1f, 0x1f, 0x1f, 0x1f, 0x1f, 0x1f, 0x1f, 0x1f, 0x00, 0xff, 0xff, 0x00,
		0x00, 0x00, 0x00, 0x00, 0x00, 0x00, 0x00, 0x00, 0x00, 0x00, 0x00, 0x00, 0x00, 0x00, 0x00, 0x00,
		0x00, 0x00, 0x00, 0x00, 0x00, 0x00, 0x00, 0x00, 0x00, 0x00, 0x00, 0x00, 0x00, 0x00, 0x00, 0x00,
		0x00, 0x00, 0x00, 0x00, 0x00, 0x00, 0x00, 0x00, 0x00, 0x00, 0x00, 0x00, 0x00, 0x00, 0x00, 0x00,
		0x00, 0x00, 0x00, 0x00, 0x00, 0x00, 0x00, 0x00, 0x00, 0x00, 0x00, 0x00, 0x00, 0x00, 0x00, 0x00,
		0x00, 0x00, 0x00, 0x00, 0x00, 0x00, 0x00, 0x00, 0x00, 0x00, 0x00, 0x00, 0x00, 0x00, 0x00, 0x00,
		0x00, 0x00, 0x00, 0x00, 0x00, 0x00, 0x00, 0x00, 0x00, 0x00, 0x00, 0x00, 0x00, 0x00, 0x00, 0x00,
		0x00, 0x00, 0x00, 0x00, 0x00, 0x00, 0x00, 0x00, 0x00, 0x00, 0x00, 0x00, 0x00, 0x03, 0x03, 0x03,
		0x03, 0x03, 0x03, 0x03, 0x03, 0x03, 0x03, 0x03, 0x03, 0x03, 0x03, 0x03, 0x03, 0x01, 0x00, 0x00};

uint8_t ptData4[] =
{ // 'j_b-removebg-1200x1200', 128x64px
		0x00, 0x00, 0x00, 0x00, 0x00, 0x00, 0x00, 0x00, 0x00, 0x00, 0x00, 0x00, 0x00, 0x00, 0x00, 0x00,
			0x00, 0x00, 0x00, 0x00, 0x00, 0x00, 0x00, 0x00, 0x00, 0x00, 0x00, 0x00, 0x00, 0x00, 0x00, 0x00,
			0x00, 0x00, 0x00, 0x00, 0x00, 0x00, 0x00, 0x00, 0x00, 0x00, 0x00, 0x00, 0x00, 0x00, 0x00, 0x00,
			0x00, 0x00, 0x00, 0x00, 0x00, 0x00, 0x00, 0x00, 0x00, 0x00, 0x00, 0x00, 0x00, 0x00, 0x00, 0x00,
			0x00, 0x00, 0x00, 0x00, 0x00, 0x00, 0x00, 0x00, 0x00, 0x00, 0x00, 0x00, 0x00, 0x00, 0x00, 0x00,
			0x00, 0x00, 0x00, 0x00, 0x00, 0x00, 0x00, 0x00, 0x00, 0x00, 0x00, 0x00, 0x00, 0x00, 0x00, 0x00,
			0x00, 0x00, 0x00, 0x00, 0x00, 0x00, 0x00, 0x00, 0x00, 0x00, 0x00, 0xc0, 0xe0, 0x60, 0x60, 0x60,
			0x78, 0x78, 0x78, 0x78, 0x78, 0x78, 0x78, 0x78, 0x60, 0x60, 0x60, 0xe0, 0xc0, 0x00, 0x00, 0x00,
			0x00, 0x00, 0x00, 0x00, 0x00, 0x00, 0x00, 0x00, 0x00, 0x00, 0x00, 0x00, 0x00, 0x00, 0x00, 0x00,
			0x00, 0x00, 0x00, 0x00, 0x00, 0x00, 0x00, 0x00, 0x00, 0x00, 0x00, 0x00, 0x00, 0x00, 0x00, 0x00,
			0x00, 0x00, 0x00, 0x00, 0x00, 0x00, 0x00, 0x00, 0x00, 0x00, 0x00, 0x00, 0x00, 0x00, 0x00, 0x00,
			0x00, 0x00, 0x00, 0x00, 0x00, 0x00, 0x00, 0x00, 0x00, 0x00, 0x00, 0x00, 0x00, 0x00, 0x00, 0x00,
			0x00, 0x00, 0x00, 0x00, 0x00, 0x00, 0x00, 0x00, 0x00, 0x00, 0x00, 0x00, 0x00, 0x00, 0x00, 0x00,
			0x00, 0x00, 0x00, 0x00, 0x00, 0x00, 0x00, 0x00, 0x00, 0x00, 0x00, 0x00, 0x00, 0x00, 0x00, 0x00,
			0x00, 0x00, 0x00, 0x00, 0x00, 0x00, 0x00, 0x00, 0x00, 0x00, 0x00, 0xff, 0x00, 0x00, 0x00, 0x00,
			0x00, 0x00, 0x00, 0x00, 0x00, 0x00, 0x00, 0x00, 0x00, 0x00, 0x00, 0x00, 0xff, 0x00, 0x00, 0x00,
			0x00, 0x00, 0x00, 0x00, 0x00, 0x00, 0x00, 0x00, 0x00, 0x00, 0x00, 0x00, 0x00, 0x00, 0x00, 0x00,
			0x00, 0x00, 0x00, 0x00, 0x00, 0x00, 0x00, 0x00, 0x00, 0x00, 0x00, 0x00, 0x00, 0x00, 0x00, 0x00,
			0x00, 0x00, 0x00, 0x00, 0x00, 0x00, 0x00, 0x00, 0x00, 0x00, 0x00, 0x00, 0x00, 0x00, 0x00, 0x00,
			0x00, 0x00, 0x00, 0x00, 0x00, 0x00, 0x00, 0x00, 0x00, 0x00, 0x00, 0x00, 0x00, 0x00, 0x00, 0x00,
			0x00, 0x00, 0x00, 0x00, 0x00, 0x00, 0x00, 0x00, 0x00, 0x00, 0x00, 0x00, 0x00, 0x00, 0x00, 0x00,
			0x00, 0x00, 0x00, 0x00, 0x00, 0x00, 0x00, 0x00, 0x00, 0x00, 0x00, 0x00, 0x00, 0x00, 0x00, 0x00,
			0x00, 0x00, 0x00, 0x00, 0x00, 0x00, 0x00, 0x00, 0x00, 0x00, 0x00, 0xff, 0x00, 0xf8, 0xf8, 0xf8,
			0xf8, 0xf8, 0xf8, 0xf8, 0xf8, 0xf8, 0xf8, 0xf8, 0xf8, 0xf8, 0xf8, 0x00, 0xff, 0x00, 0x00, 0x00,
			0x00, 0x00, 0x00, 0x00, 0x00, 0x00, 0x00, 0x00, 0x00, 0x00, 0x00, 0x00, 0x00, 0x00, 0x00, 0x00,
			0x00, 0x00, 0x00, 0x00, 0x00, 0x00, 0x00, 0x00, 0x00, 0x00, 0x00, 0x00, 0x00, 0x00, 0x00, 0x00,
			0x00, 0x00, 0x00, 0x00, 0x00, 0x00, 0x00, 0x00, 0x00, 0x00, 0x00, 0x00, 0x00, 0x00, 0x00, 0x00,
			0x00, 0x00, 0x00, 0x00, 0x00, 0x00, 0x00, 0x00, 0x00, 0x00, 0x00, 0x00, 0x00, 0x00, 0x00, 0x00,
			0x00, 0x00, 0x00, 0x00, 0x00, 0x00, 0x00, 0x00, 0x00, 0x00, 0x00, 0x00, 0x00, 0x00, 0x00, 0x00,
			0x00, 0x00, 0x00, 0x00, 0x00, 0x00, 0x00, 0x00, 0x00, 0x00, 0x00, 0x00, 0x00, 0x00, 0x00, 0x00,
			0x00, 0x00, 0x00, 0x00, 0x00, 0x00, 0x00, 0x00, 0x00, 0x00, 0x00, 0xff, 0x00, 0xe3, 0xe3, 0xe3,
			0xe3, 0xe3, 0xe3, 0xe3, 0xe3, 0xe3, 0xe3, 0xe3, 0xe3, 0xe3, 0xe3, 0x00, 0xff, 0x00, 0x00, 0x00,
			0x00, 0x00, 0x00, 0x00, 0x00, 0x00, 0x00, 0x00, 0x00, 0x00, 0x00, 0x00, 0x00, 0x00, 0x00, 0x00,
			0x00, 0x00, 0x00, 0x00, 0x00, 0x00, 0x00, 0x00, 0x00, 0x00, 0x00, 0x00, 0x00, 0x00, 0x00, 0x00,
			0x00, 0x00, 0x00, 0x00, 0x00, 0x00, 0x00, 0x00, 0x00, 0x00, 0x00, 0x00, 0x00, 0x00, 0x00, 0x00,
			0x00, 0x00, 0x00, 0x00, 0x00, 0x00, 0x00, 0x00, 0x00, 0x00, 0x00, 0x00, 0x00, 0x00, 0x00, 0x00,
			0x00, 0x00, 0x00, 0x00, 0x00, 0x00, 0x00, 0x00, 0x00, 0x00, 0x00, 0x00, 0x00, 0x00, 0x00, 0x00,
			0x00, 0x00, 0x00, 0x00, 0x00, 0x00, 0x00, 0x00, 0x00, 0x00, 0x00, 0x00, 0x00, 0x00, 0x00, 0x00,
			0x00, 0x00, 0x00, 0x00, 0x00, 0x00, 0x00, 0x00, 0x00, 0x00, 0x00, 0xff, 0x00, 0x87, 0xc7, 0xc7,
			0xc7, 0xc7, 0xc7, 0xc7, 0xc7, 0xc7, 0xc7, 0xc7, 0xc7, 0xc7, 0x87, 0x00, 0xff, 0x00, 0x00, 0x00,
			0x00, 0x00, 0x00, 0x00, 0x00, 0x00, 0x00, 0x00, 0x00, 0x00, 0x00, 0x00, 0x00, 0x00, 0x00, 0x00,
			0x00, 0x00, 0x00, 0x00, 0x00, 0x00, 0x00, 0x00, 0x00, 0x00, 0x00, 0x00, 0x00, 0x00, 0x00, 0x00,
			0x00, 0x00, 0x00, 0x00, 0x00, 0x00, 0x00, 0x00, 0x00, 0x00, 0x00, 0x00, 0x00, 0x00, 0x00, 0x00,
			0x00, 0x00, 0x00, 0x00, 0x00, 0x00, 0x00, 0x00, 0x00, 0x00, 0x00, 0x00, 0x00, 0x00, 0x00, 0x00,
			0x00, 0x00, 0x00, 0x00, 0x00, 0x00, 0x00, 0x00, 0x00, 0x00, 0x00, 0x00, 0x00, 0x00, 0x00, 0x00,
			0x00, 0x00, 0x00, 0x00, 0x00, 0x00, 0x00, 0x00, 0x00, 0x00, 0x00, 0x00, 0x00, 0x00, 0x00, 0x00,
			0x00, 0x00, 0x00, 0x00, 0x00, 0x00, 0x00, 0x00, 0x00, 0x00, 0x00, 0xff, 0x00, 0x1f, 0x1f, 0x1f,
			0x1f, 0x1f, 0x1f, 0x1f, 0x1f, 0x1f, 0x1f, 0x1f, 0x1f, 0x1f, 0x1f, 0x00, 0xff, 0x00, 0x00, 0x00,
			0x00, 0x00, 0x00, 0x00, 0x00, 0x00, 0x00, 0x00, 0x00, 0x00, 0x00, 0x00, 0x00, 0x00, 0x00, 0x00,
			0x00, 0x00, 0x00, 0x00, 0x00, 0x00, 0x00, 0x00, 0x00, 0x00, 0x00, 0x00, 0x00, 0x00, 0x00, 0x00,
			0x00, 0x00, 0x00, 0x00, 0x00, 0x00, 0x00, 0x00, 0x00, 0x00, 0x00, 0x00, 0x00, 0x00, 0x00, 0x00,
			0x00, 0x00, 0x00, 0x00, 0x00, 0x00, 0x00, 0x00, 0x00, 0x00, 0x00, 0x00, 0x00, 0x00, 0x00, 0x00,
			0x00, 0x00, 0x00, 0x00, 0x00, 0x00, 0x00, 0x00, 0x00, 0x00, 0x00, 0x00, 0x00, 0x00, 0x00, 0x00,
			0x00, 0x00, 0x00, 0x00, 0x00, 0x00, 0x00, 0x00, 0x00, 0x00, 0x00, 0x00, 0x00, 0x00, 0x00, 0x00,
			0x00, 0x00, 0x00, 0x00, 0x00, 0x00, 0x00, 0x00, 0x00, 0x00, 0x00, 0xff, 0x00, 0x3f, 0x3f, 0x3f,
			0x3f, 0x3f, 0x3f, 0x3f, 0x3f, 0x3f, 0x3f, 0x3f, 0x3f, 0x3f, 0x3f, 0x00, 0xff, 0x00, 0x00, 0x00,
			0x00, 0x00, 0x00, 0x00, 0x00, 0x00, 0x00, 0x00, 0x00, 0x00, 0x00, 0x00, 0x00, 0x00, 0x00, 0x00,
			0x00, 0x00, 0x00, 0x00, 0x00, 0x00, 0x00, 0x00, 0x00, 0x00, 0x00, 0x00, 0x00, 0x00, 0x00, 0x00,
			0x00, 0x00, 0x00, 0x00, 0x00, 0x00, 0x00, 0x00, 0x00, 0x00, 0x00, 0x00, 0x00, 0x00, 0x00, 0x00,
			0x00, 0x00, 0x00, 0x00, 0x00, 0x00, 0x00, 0x00, 0x00, 0x00, 0x00, 0x00, 0x00, 0x00, 0x00, 0x00,
			0x00, 0x00, 0x00, 0x00, 0x00, 0x00, 0x00, 0x00, 0x00, 0x00, 0x00, 0x00, 0x00, 0x00, 0x00, 0x00,
			0x00, 0x00, 0x00, 0x00, 0x00, 0x00, 0x00, 0x00, 0x00, 0x00, 0x00, 0x00, 0x00, 0x00, 0x00, 0x00,
			0x00, 0x00, 0x00, 0x00, 0x00, 0x00, 0x00, 0x00, 0x00, 0x00, 0x00, 0x03, 0x07, 0x06, 0x06, 0x06,
			0x06, 0x06, 0x06, 0x06, 0x06, 0x06, 0x06, 0x06, 0x06, 0x06, 0x06, 0x07, 0x03, 0x00, 0x00, 0x00};

uint8_t ptData5[] =
{ // 'j_b-removebg-1200x1200', 128x64px
		0x00, 0x00, 0x00, 0x00, 0x00, 0x00, 0x00, 0x00, 0x00, 0x00, 0x00, 0x00, 0x00, 0x00, 0x00, 0x00,
		0x00, 0x00, 0x00, 0x00, 0x00, 0x00, 0x00, 0x00, 0x00, 0x00, 0x00, 0x00, 0x00, 0x00, 0x00, 0x00,
		0x00, 0x00, 0x00, 0x00, 0x00, 0x00, 0x00, 0x00, 0x00, 0x00, 0x00, 0x00, 0x00, 0x00, 0x00, 0x00,
		0x00, 0x00, 0x00, 0x00, 0x00, 0x00, 0x00, 0x00, 0x00, 0x00, 0x00, 0x00, 0x00, 0x00, 0x00, 0x00,
		0x00, 0x00, 0x00, 0x00, 0x00, 0x00, 0x00, 0x00, 0x00, 0x00, 0x00, 0x00, 0x00, 0x00, 0x00, 0x00,
		0x00, 0x00, 0x00, 0x00, 0x00, 0x00, 0x00, 0x00, 0x00, 0x00, 0x00, 0x00, 0x00, 0x00, 0x00, 0x00,
		0x00, 0x00, 0x00, 0x00, 0x00, 0x00, 0x00, 0x00, 0x00, 0x00, 0x00, 0xc0, 0xe0, 0x60, 0x60, 0x60,
		0x70, 0x78, 0x78, 0x78, 0x78, 0x78, 0x78, 0x70, 0x60, 0x60, 0x60, 0xe0, 0xc0, 0x00, 0x00, 0x00,
		0x00, 0x00, 0x00, 0x00, 0x00, 0x00, 0x00, 0x00, 0x00, 0x00, 0x00, 0x00, 0x00, 0x00, 0x00, 0x00,
		0x00, 0x00, 0x00, 0x00, 0x00, 0x00, 0x00, 0x00, 0x00, 0x00, 0x00, 0x00, 0x00, 0x00, 0x00, 0x00,
		0x00, 0x00, 0x00, 0x00, 0x00, 0x00, 0x00, 0x00, 0x00, 0x00, 0x00, 0x00, 0x00, 0x00, 0x00, 0x00,
		0x00, 0x00, 0x00, 0x00, 0x00, 0x00, 0x00, 0x00, 0x00, 0x00, 0x00, 0x00, 0x00, 0x00, 0x00, 0x00,
		0x00, 0x00, 0x00, 0x00, 0x00, 0x00, 0x00, 0x00, 0x00, 0x00, 0x00, 0x00, 0x00, 0x00, 0x00, 0x00,
		0x00, 0x00, 0x00, 0x00, 0x00, 0x00, 0x00, 0x00, 0x00, 0x00, 0x00, 0x00, 0x00, 0x00, 0x00, 0x00,
		0x00, 0x00, 0x00, 0x00, 0x00, 0x00, 0x00, 0x00, 0x00, 0x00, 0x00, 0xff, 0x00, 0xfc, 0xfc, 0xfc,
		0xfc, 0xfc, 0xfc, 0xfc, 0xfc, 0xfc, 0xfc, 0xfc, 0xfc, 0xfc, 0xfc, 0x00, 0xff, 0x00, 0x00, 0x00,
		0x00, 0x00, 0x00, 0x00, 0x00, 0x00, 0x00, 0x00, 0x00, 0x00, 0x00, 0x00, 0x00, 0x00, 0x00, 0x00,
		0x00, 0x00, 0x00, 0x00, 0x00, 0x00, 0x00, 0x00, 0x00, 0x00, 0x00, 0x00, 0x00, 0x00, 0x00, 0x00,
		0x00, 0x00, 0x00, 0x00, 0x00, 0x00, 0x00, 0x00, 0x00, 0x00, 0x00, 0x00, 0x00, 0x00, 0x00, 0x00,
		0x00, 0x00, 0x00, 0x00, 0x00, 0x00, 0x00, 0x00, 0x00, 0x00, 0x00, 0x00, 0x00, 0x00, 0x00, 0x00,
		0x00, 0x00, 0x00, 0x00, 0x00, 0x00, 0x00, 0x00, 0x00, 0x00, 0x00, 0x00, 0x00, 0x00, 0x00, 0x00,
		0x00, 0x00, 0x00, 0x00, 0x00, 0x00, 0x00, 0x00, 0x00, 0x00, 0x00, 0x00, 0x00, 0x00, 0x00, 0x00,
		0x00, 0x00, 0x00, 0x00, 0x00, 0x00, 0x00, 0x00, 0x00, 0x00, 0x00, 0xff, 0x00, 0xf0, 0xf9, 0xf9,
		0xf9, 0xf9, 0xf9, 0xf9, 0xf9, 0xf9, 0xf9, 0xf9, 0xf9, 0xf9, 0xf0, 0x00, 0xff, 0x00, 0x00, 0x00,
		0x00, 0x00, 0x00, 0x00, 0x00, 0x00, 0x00, 0x00, 0x00, 0x00, 0x00, 0x00, 0x00, 0x00, 0x00, 0x00,
		0x00, 0x00, 0x00, 0x00, 0x00, 0x00, 0x00, 0x00, 0x00, 0x00, 0x00, 0x00, 0x00, 0x00, 0x00, 0x00,
		0x00, 0x00, 0x00, 0x00, 0x00, 0x00, 0x00, 0x00, 0x00, 0x00, 0x00, 0x00, 0x00, 0x00, 0x00, 0x00,
		0x00, 0x00, 0x00, 0x00, 0x00, 0x00, 0x00, 0x00, 0x00, 0x00, 0x00, 0x00, 0x00, 0x00, 0x00, 0x00,
		0x00, 0x00, 0x00, 0x00, 0x00, 0x00, 0x00, 0x00, 0x00, 0x00, 0x00, 0x00, 0x00, 0x00, 0x00, 0x00,
		0x00, 0x00, 0x00, 0x00, 0x00, 0x00, 0x00, 0x00, 0x00, 0x00, 0x00, 0x00, 0x00, 0x00, 0x00, 0x00,
		0x00, 0x00, 0x00, 0x00, 0x00, 0x00, 0x00, 0x00, 0x00, 0x00, 0x00, 0xff, 0x00, 0xe3, 0xe3, 0xe3,
		0xe3, 0xe3, 0xe3, 0xe3, 0xe3, 0xe3, 0xe3, 0xe3, 0xe3, 0xe3, 0xe3, 0x00, 0xff, 0x00, 0x00, 0x00,
		0x00, 0x00, 0x00, 0x00, 0x00, 0x00, 0x00, 0x00, 0x00, 0x00, 0x00, 0x00, 0x00, 0x00, 0x00, 0x00,
		0x00, 0x00, 0x00, 0x00, 0x00, 0x00, 0x00, 0x00, 0x00, 0x00, 0x00, 0x00, 0x00, 0x00, 0x00, 0x00,
		0x00, 0x00, 0x00, 0x00, 0x00, 0x00, 0x00, 0x00, 0x00, 0x00, 0x00, 0x00, 0x00, 0x00, 0x00, 0x00,
		0x00, 0x00, 0x00, 0x00, 0x00, 0x00, 0x00, 0x00, 0x00, 0x00, 0x00, 0x00, 0x00, 0x00, 0x00, 0x00,
		0x00, 0x00, 0x00, 0x00, 0x00, 0x00, 0x00, 0x00, 0x00, 0x00, 0x00, 0x00, 0x00, 0x00, 0x00, 0x00,
		0x00, 0x00, 0x00, 0x00, 0x00, 0x00, 0x00, 0x00, 0x00, 0x00, 0x00, 0x00, 0x00, 0x00, 0x00, 0x00,
		0x00, 0x00, 0x00, 0x00, 0x00, 0x00, 0x00, 0x00, 0x00, 0x00, 0x00, 0xff, 0x00, 0x87, 0xcf, 0xcf,
		0xcf, 0xcf, 0xcf, 0xcf, 0xcf, 0xcf, 0xcf, 0xcf, 0xcf, 0xcf, 0x87, 0x00, 0xff, 0x00, 0x00, 0x00,
		0x00, 0x00, 0x00, 0x00, 0x00, 0x00, 0x00, 0x00, 0x00, 0x00, 0x00, 0x00, 0x00, 0x00, 0x00, 0x00,
		0x00, 0x00, 0x00, 0x00, 0x00, 0x00, 0x00, 0x00, 0x00, 0x00, 0x00, 0x00, 0x00, 0x00, 0x00, 0x00,
		0x00, 0x00, 0x00, 0x00, 0x00, 0x00, 0x00, 0x00, 0x00, 0x00, 0x00, 0x00, 0x00, 0x00, 0x00, 0x00,
		0x00, 0x00, 0x00, 0x00, 0x00, 0x00, 0x00, 0x00, 0x00, 0x00, 0x00, 0x00, 0x00, 0x00, 0x00, 0x00,
		0x00, 0x00, 0x00, 0x00, 0x00, 0x00, 0x00, 0x00, 0x00, 0x00, 0x00, 0x00, 0x00, 0x00, 0x00, 0x00,
		0x00, 0x00, 0x00, 0x00, 0x00, 0x00, 0x00, 0x00, 0x00, 0x00, 0x00, 0x00, 0x00, 0x00, 0x00, 0x00,
		0x00, 0x00, 0x00, 0x00, 0x00, 0x00, 0x00, 0x00, 0x00, 0x00, 0x00, 0xff, 0x00, 0x1f, 0x1f, 0x1f,
		0x1f, 0x1f, 0x1f, 0x1f, 0x1f, 0x1f, 0x1f, 0x1f, 0x1f, 0x1f, 0x1f, 0x00, 0xff, 0x00, 0x00, 0x00,
		0x00, 0x00, 0x00, 0x00, 0x00, 0x00, 0x00, 0x00, 0x00, 0x00, 0x00, 0x00, 0x00, 0x00, 0x00, 0x00,
		0x00, 0x00, 0x00, 0x00, 0x00, 0x00, 0x00, 0x00, 0x00, 0x00, 0x00, 0x00, 0x00, 0x00, 0x00, 0x00,
		0x00, 0x00, 0x00, 0x00, 0x00, 0x00, 0x00, 0x00, 0x00, 0x00, 0x00, 0x00, 0x00, 0x00, 0x00, 0x00,
		0x00, 0x00, 0x00, 0x00, 0x00, 0x00, 0x00, 0x00, 0x00, 0x00, 0x00, 0x00, 0x00, 0x00, 0x00, 0x00,
		0x00, 0x00, 0x00, 0x00, 0x00, 0x00, 0x00, 0x00, 0x00, 0x00, 0x00, 0x00, 0x00, 0x00, 0x00, 0x00,
		0x00, 0x00, 0x00, 0x00, 0x00, 0x00, 0x00, 0x00, 0x00, 0x00, 0x00, 0x00, 0x00, 0x00, 0x00, 0x00,
		0x00, 0x00, 0x00, 0x00, 0x00, 0x00, 0x00, 0x00, 0x00, 0x00, 0x00, 0xff, 0x00, 0x3f, 0x7f, 0x7f,
		0x7f, 0x7f, 0x7f, 0x7f, 0x7f, 0x7f, 0x7f, 0x7f, 0x7f, 0x7f, 0x3f, 0x00, 0xff, 0x00, 0x00, 0x00,
		0x00, 0x00, 0x00, 0x00, 0x00, 0x00, 0x00, 0x00, 0x00, 0x00, 0x00, 0x00, 0x00, 0x00, 0x00, 0x00,
		0x00, 0x00, 0x00, 0x00, 0x00, 0x00, 0x00, 0x00, 0x00, 0x00, 0x00, 0x00, 0x00, 0x00, 0x00, 0x00,
		0x00, 0x00, 0x00, 0x00, 0x00, 0x00, 0x00, 0x00, 0x00, 0x00, 0x00, 0x00, 0x00, 0x00, 0x00, 0x00,
		0x00, 0x00, 0x00, 0x00, 0x00, 0x00, 0x00, 0x00, 0x00, 0x00, 0x00, 0x00, 0x00, 0x00, 0x00, 0x00,
		0x00, 0x00, 0x00, 0x00, 0x00, 0x00, 0x00, 0x00, 0x00, 0x00, 0x00, 0x00, 0x00, 0x00, 0x00, 0x00,
		0x00, 0x00, 0x00, 0x00, 0x00, 0x00, 0x00, 0x00, 0x00, 0x00, 0x00, 0x00, 0x00, 0x00, 0x00, 0x00,
		0x00, 0x00, 0x00, 0x00, 0x00, 0x00, 0x00, 0x00, 0x00, 0x00, 0x00, 0x03, 0x06, 0x06, 0x06, 0x06,
		0x06, 0x06, 0x06, 0x06, 0x06, 0x06, 0x06, 0x06, 0x06, 0x06, 0x06, 0x06, 0x03, 0x00, 0x00, 0x00};

uint8_t termometrupoza[] =
{
		0x00, 0x00, 0x00, 0x00, 0x00, 0x00, 0x00, 0x00, 0x00, 0x00, 0x00, 0x00, 0x00, 0x00, 0x00, 0x00,
		0x00, 0x00, 0x00, 0x00, 0x00, 0x00, 0x00, 0x00, 0x00, 0x00, 0x00, 0x00, 0x00, 0x00, 0x00, 0x00,
		0x00, 0x00, 0x00, 0x00, 0x00, 0x00, 0x00, 0x00, 0x00, 0x00, 0x00, 0x00, 0x00, 0x00, 0x00, 0x00,
		0x00, 0x00, 0x00, 0x00, 0x00, 0x00, 0x00, 0x00, 0x00, 0x00, 0x00, 0x00, 0x00, 0x00, 0x00, 0x00,
		0x00, 0x00, 0x00, 0x00, 0x00, 0x00, 0x00, 0x00, 0x00, 0x00, 0x00, 0x00, 0x00, 0x00, 0x00, 0x00,
		0x00, 0x00, 0x00, 0x00, 0x00, 0x00, 0x00, 0x00, 0x00, 0x00, 0x00, 0x00, 0x00, 0x00, 0x00, 0x00,
		0x00, 0x00, 0x00, 0x00, 0x00, 0x00, 0x00, 0x00, 0x00, 0x00, 0x00, 0x00, 0x00, 0x00, 0xe0, 0xf8,
		0x18, 0x0c, 0x0c, 0x04, 0x04, 0x0c, 0x0c, 0x38, 0xf0, 0x80, 0x00, 0x00, 0x00, 0x00, 0x00, 0x00,
		0x00, 0x00, 0x00, 0x00, 0x00, 0x00, 0x00, 0x00, 0x00, 0x00, 0x00, 0x00, 0x00, 0x00, 0x00, 0x00,
		0x00, 0x00, 0x00, 0x00, 0x00, 0x00, 0x00, 0x00, 0x00, 0x00, 0x00, 0x00, 0x00, 0x00, 0x00, 0x00,
		0x00, 0x00, 0x00, 0x00, 0x00, 0x00, 0x00, 0x00, 0x00, 0x00, 0x00, 0x00, 0x00, 0x00, 0x00, 0x00,
		0x00, 0x00, 0x00, 0x00, 0x00, 0x00, 0x00, 0x00, 0x00, 0x00, 0x00, 0x00, 0x00, 0x00, 0x00, 0x00,
		0x00, 0x00, 0x00, 0x00, 0x00, 0x00, 0x00, 0x00, 0x00, 0x00, 0x00, 0x00, 0x00, 0x00, 0x00, 0x00,
		0x00, 0x00, 0x00, 0x00, 0x00, 0x00, 0x00, 0x00, 0x00, 0x00, 0x00, 0x00, 0x00, 0x00, 0x00, 0x00,
		0x00, 0x00, 0x00, 0x00, 0x00, 0x00, 0x00, 0x00, 0x00, 0x00, 0x20, 0x20, 0x20, 0x20, 0xff, 0xff,
		0x00, 0x00, 0x00, 0x00, 0x00, 0x00, 0x00, 0x00, 0xff, 0xff, 0x00, 0x00, 0x00, 0x00, 0x00, 0x00,
		0x00, 0x00, 0x00, 0x00, 0x00, 0x00, 0x00, 0x00, 0x00, 0x00, 0x00, 0x00, 0x00, 0x00, 0x00, 0x00,
		0x00, 0x00, 0x00, 0x00, 0x00, 0x00, 0x00, 0x00, 0x00, 0x00, 0x00, 0x00, 0x00, 0x00, 0x00, 0x00,
		0x00, 0x00, 0x00, 0x00, 0x00, 0x00, 0x00, 0x00, 0x00, 0x00, 0x00, 0x00, 0x00, 0x00, 0x00, 0x00,
		0x00, 0x00, 0x00, 0x00, 0x00, 0x00, 0x00, 0x00, 0x00, 0x00, 0x00, 0x00, 0x00, 0x00, 0x00, 0x00,
		0x00, 0x00, 0x00, 0x00, 0x00, 0x00, 0x00, 0x00, 0x00, 0x00, 0x00, 0x00, 0x00, 0x00, 0x00, 0x00,
		0x00, 0x00, 0x00, 0x00, 0x00, 0x00, 0x00, 0x00, 0x00, 0x00, 0x00, 0x00, 0x00, 0x00, 0x00, 0x00,
		0x00, 0x00, 0x00, 0x00, 0x00, 0x00, 0x00, 0x00, 0x00, 0x00, 0x30, 0x30, 0x30, 0x30, 0xff, 0xff,
		0x00, 0x00, 0x00, 0x00, 0x00, 0x00, 0x00, 0x00, 0xff, 0xff, 0x00, 0x00, 0x00, 0x00, 0x00, 0x00,
		0x00, 0x00, 0x00, 0x00, 0x00, 0x00, 0x00, 0x00, 0x00, 0x00, 0x00, 0x00, 0x00, 0x00, 0x00, 0x00,
		0x00, 0x00, 0x00, 0x00, 0x00, 0x00, 0x00, 0x00, 0x00, 0x00, 0x00, 0x00, 0x00, 0x00, 0x00, 0x00,
		0x00, 0x00, 0x00, 0x00, 0x00, 0x00, 0x00, 0x00, 0x00, 0x00, 0x00, 0x00, 0x00, 0x00, 0x00, 0x00,
		0x00, 0x00, 0x00, 0x00, 0x00, 0x00, 0x00, 0x00, 0x00, 0x00, 0x00, 0x00, 0x00, 0x00, 0x00, 0x00,
		0x00, 0x00, 0x00, 0x00, 0x00, 0x00, 0x00, 0x00, 0x00, 0x00, 0x00, 0x00, 0x00, 0x00, 0x00, 0x00,
		0x00, 0x00, 0x00, 0x00, 0x00, 0x00, 0x00, 0x00, 0x00, 0x00, 0x00, 0x00, 0x00, 0x00, 0x00, 0x00,
		0x00, 0x00, 0x00, 0x00, 0x00, 0x00, 0x00, 0x00, 0x00, 0x00, 0x20, 0x60, 0x60, 0x60, 0xff, 0xff,
		0x00, 0x00, 0x00, 0x00, 0x00, 0x00, 0x00, 0x00, 0xff, 0xff, 0x00, 0x00, 0x00, 0x00, 0x00, 0x00,
		0x00, 0x00, 0x00, 0x00, 0x00, 0x00, 0x00, 0x00, 0x00, 0x00, 0x00, 0x00, 0x00, 0x00, 0x00, 0x00,
		0x00, 0x00, 0x00, 0x00, 0x00, 0x00, 0x00, 0x00, 0x00, 0x00, 0x00, 0x00, 0x00, 0x00, 0x00, 0x00,
		0x00, 0x00, 0x00, 0x00, 0x00, 0x00, 0x00, 0x00, 0x00, 0x00, 0x00, 0x00, 0x00, 0x00, 0x00, 0x00,
		0x00, 0x00, 0x00, 0x00, 0x00, 0x00, 0x00, 0x00, 0x00, 0x00, 0x00, 0x00, 0x00, 0x00, 0x00, 0x00,
		0x00, 0x00, 0x00, 0x00, 0x00, 0x00, 0x00, 0x00, 0x00, 0x00, 0x00, 0x00, 0x00, 0x00, 0x00, 0x00,
		0x00, 0x00, 0x00, 0x00, 0x00, 0x00, 0x00, 0x00, 0x00, 0x00, 0x00, 0x00, 0x00, 0x00, 0x00, 0x00,
		0x00, 0x00, 0x00, 0x00, 0x00, 0x00, 0x00, 0x00, 0x00, 0x00, 0x20, 0x30, 0x30, 0x30, 0xff, 0xff,
		0x00, 0x00, 0x00, 0x00, 0x00, 0x00, 0x00, 0x00, 0xff, 0xff, 0x00, 0x00, 0x00, 0x00, 0x00, 0x00,
		0x00, 0x00, 0x00, 0x00, 0x00, 0x00, 0x00, 0x00, 0x00, 0x00, 0x00, 0x00, 0x00, 0x00, 0x00, 0x00,
		0x00, 0x00, 0x00, 0x00, 0x00, 0x00, 0x00, 0x00, 0x00, 0x00, 0x00, 0x00, 0x00, 0x00, 0x00, 0x00,
		0x00, 0x00, 0x00, 0x00, 0x00, 0x00, 0x00, 0x00, 0x00, 0x00, 0x00, 0x00, 0x00, 0x00, 0x00, 0x00,
		0x00, 0x00, 0x00, 0x00, 0x00, 0x00, 0x00, 0x00, 0x00, 0x00, 0x00, 0x00, 0x00, 0x00, 0x00, 0x00,
		0x00, 0x00, 0x00, 0x00, 0x00, 0x00, 0x00, 0x00, 0x00, 0x00, 0x00, 0x00, 0x00, 0x00, 0x00, 0x00,
		0x00, 0x00, 0x00, 0x00, 0x00, 0x00, 0x00, 0x00, 0x00, 0x00, 0x00, 0x00, 0x00, 0x00, 0x00, 0x00,
		0x00, 0x00, 0x00, 0x00, 0x00, 0x00, 0x00, 0x00, 0x00, 0xc0, 0xf0, 0x38, 0x1c, 0xce, 0xe7, 0xf3,
		0xf0, 0xf8, 0xf8, 0xf8, 0xf8, 0xf8, 0xf8, 0xf0, 0xf3, 0xe7, 0xcc, 0x1c, 0x78, 0xe0, 0x80, 0x00,
		0x00, 0x00, 0x00, 0x00, 0x00, 0x00, 0x00, 0x00, 0x00, 0x00, 0x00, 0x00, 0x00, 0x00, 0x00, 0x00,
		0x00, 0x00, 0x00, 0x00, 0x00, 0x00, 0x00, 0x00, 0x00, 0x00, 0x00, 0x00, 0x00, 0x00, 0x00, 0x00,
		0x00, 0x00, 0x00, 0x00, 0x00, 0x00, 0x00, 0x00, 0x00, 0x00, 0x00, 0x00, 0x00, 0x00, 0x00, 0x00,
		0x00, 0x00, 0x00, 0x00, 0x00, 0x00, 0x00, 0x00, 0x00, 0x00, 0x00, 0x00, 0x00, 0x00, 0x00, 0x00,
		0x00, 0x00, 0x00, 0x00, 0x00, 0x00, 0x00, 0x00, 0x00, 0x00, 0x00, 0x00, 0x00, 0x00, 0x00, 0x00,
		0x00, 0x00, 0x00, 0x00, 0x00, 0x00, 0x00, 0x00, 0x00, 0x00, 0x00, 0x00, 0x00, 0x00, 0x00, 0x00,
		0x00, 0x00, 0x00, 0x00, 0x00, 0x00, 0x00, 0x00, 0x00, 0x7f, 0xf1, 0x80, 0x1f, 0x7f, 0xff, 0xff,
		0xff, 0xff, 0xff, 0xff, 0xff, 0xff, 0xff, 0xff, 0xff, 0xff, 0x7f, 0x0e, 0xc0, 0xff, 0x3f, 0x00,
		0x00, 0x00, 0x00, 0x00, 0x00, 0x00, 0x00, 0x00, 0x00, 0x00, 0x00, 0x00, 0x00, 0x00, 0x00, 0x00,
		0x00, 0x00, 0x00, 0x00, 0x00, 0x00, 0x00, 0x00, 0x00, 0x00, 0x00, 0x00, 0x00, 0x00, 0x00, 0x00,
		0x00, 0x00, 0x00, 0x00, 0x00, 0x00, 0x00, 0x00, 0x00, 0x00, 0x00, 0x00, 0x00, 0x00, 0x00, 0x00,
		0x00, 0x00, 0x00, 0x00, 0x00, 0x00, 0x00, 0x00, 0x00, 0x00, 0x00, 0x00, 0x00, 0x00, 0x00, 0x00,
		0x00, 0x00, 0x00, 0x00, 0x00, 0x00, 0x00, 0x00, 0x00, 0x00, 0x00, 0x00, 0x00, 0x00, 0x00, 0x00,
		0x00, 0x00, 0x00, 0x00, 0x00, 0x00, 0x00, 0x00, 0x00, 0x00, 0x00, 0x00, 0x00, 0x00, 0x00, 0x00,
		0x00, 0x00, 0x00, 0x00, 0x00, 0x00, 0x00, 0x00, 0x00, 0x00, 0x01, 0x03, 0x07, 0x0e, 0x0c, 0x19,
		0x1b, 0x33, 0x33, 0x33, 0x33, 0x33, 0x13, 0x19, 0x19, 0x0c, 0x0e, 0x07, 0x03, 0x00, 0x00, 0x00};

uint8_t pozanalog[] =
{
		0x00, 0x00, 0x00, 0x00, 0x00, 0x00, 0x00, 0x00, 0x00, 0x00, 0x00, 0x00, 0x00, 0x00, 0x00, 0x00,
		0x00, 0x00, 0x00, 0x00, 0x00, 0x00, 0x00, 0x00, 0x00, 0x00, 0x00, 0x00, 0x00, 0x00, 0x00, 0x00,
		0x00, 0x00, 0x00, 0x00, 0x00, 0x00, 0x00, 0x00, 0x00, 0x00, 0x08, 0x0c, 0x0c, 0x84, 0xfc, 0xfc,
		0x38, 0x00, 0x00, 0x00, 0x00, 0x00, 0x00, 0x00, 0x00, 0x00, 0x00, 0x00, 0x00, 0x00, 0x00, 0x00,
		0x00, 0x00, 0x00, 0x00, 0x00, 0x00, 0x00, 0x00, 0x00, 0x00, 0x00, 0x00, 0x00, 0x00, 0x00, 0x00,
		0x08, 0x0c, 0x4c, 0x44, 0xfc, 0xfc, 0xb8, 0x00, 0x00, 0x00, 0x00, 0x00, 0x00, 0x00, 0x00, 0x00,
		0x00, 0x00, 0x00, 0x00, 0x00, 0x00, 0x00, 0x00, 0x00, 0x00, 0x00, 0x00, 0x00, 0x00, 0x00, 0x00,
		0x00, 0x00, 0x00, 0x00, 0x00, 0x00, 0x00, 0x00, 0x00, 0x00, 0x00, 0x00, 0x00, 0x00, 0x00, 0x00,
		0x00, 0x00, 0x00, 0x00, 0x00, 0x00, 0x00, 0x00, 0x00, 0x00, 0x00, 0x00, 0x00, 0x00, 0x00, 0x00,
		0x02, 0x02, 0xff, 0xff, 0x00, 0x00, 0x00, 0x00, 0x00, 0x00, 0x00, 0x00, 0x00, 0x00, 0x00, 0x00,
		0x00, 0x00, 0x00, 0x00, 0x00, 0x00, 0x00, 0x00, 0x00, 0x00, 0x04, 0x06, 0x07, 0x05, 0x25, 0xe4,
		0x84, 0x04, 0x00, 0x00, 0x00, 0x00, 0x00, 0x00, 0x00, 0x00, 0x00, 0x00, 0x00, 0x00, 0x00, 0x00,
		0x00, 0x00, 0x00, 0x00, 0x00, 0x00, 0x00, 0x00, 0x00, 0x00, 0x00, 0x00, 0x00, 0x00, 0x00, 0x00,
		0x02, 0x06, 0x86, 0xc4, 0x46, 0x07, 0x03, 0x00, 0x00, 0x00, 0x00, 0x00, 0x00, 0x00, 0x00, 0x00,
		0x00, 0x00, 0x00, 0x00, 0x00, 0x00, 0x00, 0x30, 0x38, 0x3c, 0x2e, 0xff, 0xff, 0xff, 0x20, 0x00,
		0x00, 0x00, 0x00, 0x00, 0x00, 0x00, 0x00, 0x00, 0x00, 0x00, 0x00, 0x00, 0x00, 0x00, 0x00, 0x00,
		0x80, 0xe0, 0xe0, 0x20, 0x60, 0xe0, 0xc0, 0x00, 0x00, 0x00, 0x00, 0x00, 0x00, 0x00, 0x00, 0x00,
		0x01, 0x01, 0x01, 0x01, 0x01, 0x21, 0x70, 0xe0, 0x80, 0x00, 0x00, 0x00, 0x00, 0x00, 0x00, 0x00,
		0x00, 0x00, 0x00, 0x00, 0x40, 0xc0, 0x80, 0x00, 0x00, 0x00, 0x00, 0x00, 0x00, 0x00, 0x00, 0x01,
		0x0f, 0x7c, 0xe0, 0x00, 0x00, 0x00, 0x00, 0x00, 0x00, 0x00, 0x00, 0x00, 0x00, 0x00, 0x00, 0x1c,
		0xfc, 0xe0, 0x00, 0x00, 0x00, 0x00, 0x00, 0x00, 0x00, 0x00, 0x00, 0x00, 0x00, 0x00, 0x00, 0xc0,
		0xf0, 0x3e, 0x07, 0x01, 0x00, 0x00, 0x00, 0x00, 0x00, 0x00, 0x80, 0xe0, 0x40, 0x00, 0x00, 0x00,
		0x00, 0x00, 0x00, 0x00, 0x00, 0x00, 0x00, 0x80, 0xc0, 0x60, 0x20, 0x01, 0x01, 0x01, 0x00, 0x00,
		0x00, 0x00, 0x00, 0x00, 0x00, 0x00, 0x00, 0x00, 0x00, 0xf0, 0xf0, 0xf0, 0x90, 0x90, 0x10, 0x00,
		0x0f, 0x3f, 0x3f, 0x20, 0x30, 0x3f, 0x1f, 0x07, 0x00, 0x00, 0x00, 0x00, 0x00, 0x00, 0x00, 0x00,
		0x00, 0x00, 0x00, 0x00, 0x00, 0x00, 0x00, 0x01, 0x03, 0x0f, 0x1c, 0x78, 0xe0, 0xc0, 0x80, 0xc0,
		0xc0, 0x60, 0x60, 0x60, 0x30, 0x33, 0x37, 0x1c, 0x18, 0x18, 0x18, 0x0c, 0x0c, 0x0c, 0x0c, 0x06,
		0x06, 0x06, 0x07, 0x07, 0x06, 0x06, 0x03, 0x03, 0x03, 0x03, 0x03, 0x03, 0x03, 0x03, 0x03, 0x03,
		0x03, 0x03, 0x03, 0x03, 0x03, 0x03, 0x03, 0x03, 0x03, 0x03, 0x06, 0x06, 0x06, 0x06, 0x07, 0x07,
		0x06, 0x0c, 0x0c, 0x0c, 0x0c, 0x18, 0x18, 0x18, 0x1c, 0x3f, 0x33, 0x31, 0x60, 0x60, 0x60, 0xc0,
		0xc0, 0xc0, 0xe0, 0x30, 0x18, 0x0e, 0x07, 0x01, 0x00, 0x00, 0x00, 0x00, 0x00, 0x00, 0x00, 0x00,
		0x00, 0x00, 0x00, 0x00, 0x00, 0x00, 0x00, 0x00, 0x08, 0x18, 0x18, 0x10, 0x19, 0x1f, 0x0f, 0x00,
		0x00, 0x00, 0x00, 0x00, 0x02, 0x04, 0x08, 0x10, 0x20, 0x40, 0x80, 0x00, 0x00, 0x00, 0x00, 0x00,
		0x00, 0x01, 0x82, 0xc4, 0xe8, 0x70, 0x38, 0x18, 0x0c, 0x0e, 0x06, 0x03, 0x03, 0x01, 0x01, 0x00,
		0x00, 0x00, 0x00, 0x00, 0x00, 0x00, 0x00, 0x00, 0x00, 0x00, 0x00, 0x00, 0x00, 0x00, 0x00, 0x00,
		0x00, 0x00, 0x00, 0x00, 0x00, 0x00, 0x00, 0x00, 0x00, 0x00, 0x00, 0x00, 0x00, 0x00, 0x00, 0x00,
		0x00, 0x00, 0x00, 0x00, 0x00, 0x00, 0x00, 0x00, 0x00, 0x00, 0x00, 0x00, 0x00, 0x00, 0x00, 0x00,
		0x00, 0x00, 0x00, 0x00, 0x00, 0x00, 0x00, 0x00, 0x00, 0x00, 0x00, 0x00, 0x00, 0x00, 0x00, 0x00,
		0x00, 0x01, 0x01, 0x03, 0x03, 0x06, 0x0e, 0x0c, 0x18, 0x38, 0x78, 0xe4, 0xc2, 0x81, 0x00, 0x00,
		0x00, 0x00, 0x80, 0x80, 0xc0, 0x60, 0x30, 0x38, 0x1c, 0x0e, 0x07, 0x02, 0x00, 0x00, 0x00, 0x00,
		0x00, 0x00, 0x00, 0x00, 0x00, 0x00, 0x00, 0x00, 0x00, 0x00, 0x00, 0x01, 0x02, 0x04, 0x08, 0x08,
		0x0e, 0x07, 0x03, 0x01, 0x00, 0x00, 0x00, 0x00, 0x00, 0x00, 0x00, 0x00, 0x00, 0x00, 0x00, 0x00,
		0x00, 0x00, 0x00, 0x00, 0x00, 0x00, 0x00, 0x00, 0x00, 0x00, 0x00, 0x00, 0x00, 0x00, 0x00, 0x00,
		0x00, 0x00, 0x00, 0x00, 0x00, 0x00, 0x00, 0x00, 0x00, 0x00, 0x00, 0x00, 0x00, 0x00, 0x00, 0x00,
		0x00, 0x00, 0x00, 0x00, 0x00, 0x00, 0x00, 0x00, 0x00, 0x00, 0x00, 0x00, 0x00, 0x00, 0x00, 0x00,
		0x00, 0x00, 0x00, 0x00, 0x00, 0x00, 0x00, 0x00, 0x00, 0x00, 0x00, 0x00, 0x00, 0x00, 0x00, 0x00,
		0x00, 0x00, 0x00, 0x00, 0x00, 0x00, 0x00, 0x00, 0x00, 0x00, 0x00, 0x00, 0x01, 0x03, 0x07, 0x0e,
		0x0e, 0x07, 0x03, 0x01, 0x00, 0x00, 0x00, 0x00, 0x00, 0x00, 0x00, 0x00, 0x00, 0x00, 0x00, 0x00,
		0x00, 0x00, 0x00, 0x00, 0x00, 0x00, 0x00, 0x00, 0x00, 0x00, 0x00, 0x00, 0x00, 0x00, 0x00, 0x00,
		0x00, 0x00, 0x00, 0x00, 0x00, 0x00, 0x00, 0x00, 0x00, 0x00, 0x00, 0x00, 0x00, 0x00, 0x00, 0x00,
		0x00, 0x00, 0x00, 0x00, 0x00, 0x00, 0x00, 0x00, 0x00, 0x00, 0x00, 0x00, 0x00, 0x00, 0x00, 0x00,
		0x00, 0x00, 0x00, 0x00, 0x00, 0x00, 0x00, 0x00, 0x00, 0x00, 0x00, 0x00, 0x00, 0x00, 0x00, 0x00,
		0x00, 0x00, 0x00, 0x00, 0x00, 0x00, 0x00, 0x00, 0x00, 0x00, 0x00, 0x00, 0x00, 0x00, 0x00, 0x00,
		0x00, 0x00, 0x00, 0x00, 0x00, 0x00, 0x00, 0x00, 0x00, 0x00, 0x00, 0x00, 0x00, 0x00, 0x00, 0x00,
		0x00, 0x00, 0x00, 0x00, 0x00, 0x00, 0x00, 0x00, 0x00, 0x00, 0x00, 0x00, 0x00, 0x00, 0x00, 0x00,
		0x00, 0x00, 0x00, 0x00, 0x00, 0x00, 0x00, 0x00, 0x00, 0x00, 0x00, 0x00, 0x00, 0x00, 0x00, 0x00,
		0x00, 0x00, 0x00, 0x00, 0x00, 0x00, 0x00, 0x00, 0x00, 0x00, 0x00, 0x00, 0x00, 0x00, 0x00, 0x00,
		0x00, 0x00, 0x00, 0x00, 0x00, 0x00, 0x00, 0x00, 0x00, 0x00, 0x00, 0x00, 0x00, 0x00, 0x00, 0x00,
		0x00, 0x00, 0x00, 0x00, 0x00, 0x00, 0x00, 0x00, 0x00, 0x00, 0x00, 0x00, 0x00, 0x00, 0x00, 0x00,
		0x00, 0x00, 0x00, 0x00, 0x00, 0x00, 0x00, 0x00, 0x00, 0x00, 0x00, 0x00, 0x00, 0x00, 0x00, 0x00,
		0x00, 0x00, 0x00, 0x00, 0x00, 0x00, 0x00, 0x00, 0x00, 0x00, 0x00, 0x00, 0x00, 0x00, 0x00, 0x00,
		0x00, 0x00, 0x00, 0x00, 0x00, 0x00, 0x00, 0x00, 0x00, 0x00, 0x00, 0x00, 0x00, 0x00, 0x00, 0x00,
		0x00, 0x00, 0x00, 0x00, 0x00, 0x00, 0x00, 0x00, 0x00, 0x00, 0x00, 0x00, 0x00, 0x00, 0x00, 0x00,
		0x00, 0x00, 0x00, 0x00, 0x00, 0x00, 0x00, 0x00, 0x00, 0x00, 0x00, 0x00, 0x00, 0x00, 0x00, 0x00};

uint8_t pozafall[] =
{
		0x00, 0x00, 0x00, 0x00, 0x00, 0x00, 0x00, 0x00, 0x00, 0xff, 0x00, 0x00, 0x08, 0x00, 0x00, 0x00,
			0x00, 0x1e, 0x00, 0x00, 0x01, 0x00, 0x00, 0xff, 0x00, 0x00, 0x00, 0x00, 0x00, 0x00, 0x00, 0x00,
			0x00, 0x00, 0x00, 0x00, 0x00, 0x00, 0x00, 0x00, 0x00, 0x00, 0x00, 0x00, 0x00, 0x01, 0x00, 0x00,
			0x00, 0x00, 0x00, 0x00, 0x00, 0x00, 0x00, 0x00, 0x84, 0x00, 0x00, 0x00, 0x00, 0x00, 0xfc, 0x00,
			0x00, 0x00, 0x00, 0x00, 0x00, 0x00, 0x00, 0x00, 0x00, 0x00, 0x00, 0x00, 0x00, 0x00, 0x00, 0x00,
			0x00, 0x00, 0x00, 0x00, 0x02, 0x00, 0x00, 0x00, 0x00, 0x00, 0xa5, 0x00, 0x00, 0x00, 0x00, 0x00,
			0x9c, 0x00, 0x00, 0x00, 0x00, 0x01, 0x00, 0x00, 0x00, 0x00, 0x00, 0x00, 0x00, 0x00, 0x00, 0x00,
			0x00, 0x00, 0x00, 0x00, 0x00, 0x00, 0x00, 0x00, 0x00, 0x00, 0x00, 0x00, 0x00, 0x00, 0x00, 0x00,
			0x00, 0x00, 0x00, 0x00, 0x00, 0x00, 0x00, 0x00, 0x00, 0x0f, 0x00, 0x00, 0x08, 0x00, 0x00, 0x00,
			0x00, 0x03, 0x00, 0x00, 0x08, 0x00, 0x00, 0x0f, 0x00, 0x00, 0x00, 0x00, 0x00, 0x00, 0x00, 0x00,
			0x00, 0x00, 0x08, 0x00, 0x00, 0x00, 0x00, 0x00, 0x00, 0x00, 0x00, 0x00, 0x00, 0x00, 0x00, 0x00,
			0x00, 0x00, 0x00, 0x00, 0x00, 0x00, 0x08, 0x00, 0x03, 0x00, 0x00, 0x00, 0x00, 0x00, 0x0f, 0x00,
			0x00, 0x00, 0x00, 0x00, 0x00, 0x00, 0x00, 0x00, 0x00, 0x00, 0x00, 0x00, 0x00, 0x00, 0x00, 0x08,
			0x00, 0x00, 0x00, 0x00, 0x03, 0x00, 0x00, 0x00, 0x00, 0x00, 0x0a, 0x00, 0x00, 0x08, 0x00, 0x00,
			0x01, 0x00, 0x00, 0x00, 0x00, 0x08, 0x00, 0x00, 0x00, 0x00, 0x00, 0x00, 0x00, 0x00, 0x00, 0x00,
			0x00, 0x00, 0x00, 0x00, 0x00, 0x00, 0x00, 0x00, 0x00, 0x00, 0x00, 0x00, 0x00, 0x00, 0x00, 0x00,
			0x00, 0x00, 0x00, 0x00, 0x00, 0x00, 0x04, 0x00, 0x00, 0x82, 0x00, 0x00, 0x00, 0x00, 0x00, 0x38,
			0x00, 0x00, 0x00, 0x00, 0x00, 0x00, 0x00, 0xc2, 0x00, 0x00, 0x00, 0x00, 0x80, 0xe0, 0x00, 0x04,
			0x00, 0x00, 0x00, 0x00, 0x00, 0x00, 0x00, 0x00, 0x14, 0x00, 0x00, 0x00, 0x00, 0x04, 0x00, 0x00,
			0x00, 0x00, 0x00, 0x00, 0x00, 0x00, 0x00, 0x00, 0x00, 0x00, 0x00, 0x00, 0x00, 0x00, 0x00, 0x00,
			0x00, 0x00, 0x00, 0x00, 0x00, 0x00, 0x00, 0x00, 0x00, 0x04, 0x00, 0x00, 0x00, 0x00, 0x00, 0x00,
			0x00, 0x00, 0x00, 0x00, 0x00, 0x00, 0x00, 0x00, 0x00, 0x00, 0x00, 0x00, 0x00, 0x00, 0x00, 0x00,
			0x30, 0x00, 0x00, 0x00, 0x00, 0x00, 0x00, 0x00, 0x00, 0x00, 0x00, 0x00, 0x00, 0x00, 0x00, 0x00,
			0x00, 0x00, 0x00, 0x02, 0x00, 0x00, 0x00, 0x00, 0x00, 0x00, 0x00, 0x00, 0x00, 0x00, 0x00, 0x00,
			0x00, 0x00, 0x00, 0x00, 0x00, 0x00, 0x20, 0x00, 0x00, 0x20, 0x00, 0x00, 0x00, 0x00, 0x00, 0x0e,
			0x00, 0x00, 0x00, 0x00, 0x00, 0x00, 0x00, 0x20, 0x00, 0x00, 0x00, 0x00, 0x01, 0x03, 0x00, 0x20,
			0x00, 0x00, 0x00, 0x00, 0x00, 0x20, 0x00, 0x00, 0x10, 0x00, 0x00, 0x00, 0x00, 0x14, 0x00, 0x00,
			0x00, 0x00, 0x00, 0x00, 0x00, 0x00, 0x00, 0x00, 0x00, 0x00, 0x00, 0x00, 0x00, 0x00, 0x00, 0x00,
			0x00, 0x00, 0x00, 0x00, 0x00, 0x00, 0x00, 0x00, 0x00, 0x20, 0x00, 0x00, 0x00, 0x00, 0x00, 0x20,
			0x00, 0x00, 0x00, 0x00, 0x00, 0x00, 0x00, 0x00, 0x00, 0x00, 0x00, 0x00, 0x00, 0x20, 0x00, 0x00,
			0x05, 0x00, 0x00, 0x00, 0x00, 0x00, 0x00, 0x00, 0x00, 0x00, 0x00, 0x00, 0x00, 0x00, 0x00, 0x00,
			0x00, 0x00, 0x00, 0x22, 0x00, 0x00, 0x00, 0x00, 0x00, 0x00, 0x00, 0x00, 0x00, 0x00, 0x00, 0x00,
			0x00, 0x00, 0x00, 0x00, 0x00, 0x00, 0x00, 0x00, 0x00, 0x00, 0x00, 0x00, 0x00, 0x00, 0x00, 0x00,
			0x00, 0x00, 0x00, 0x00, 0x00, 0x00, 0x00, 0x00, 0x00, 0x00, 0xd0, 0x00, 0x00, 0x00, 0x00, 0x00,
			0x00, 0x00, 0x18, 0x00, 0x00, 0x08, 0x00, 0x00, 0x00, 0x00, 0x00, 0x00, 0x00, 0x00, 0x00, 0x00,
			0x08, 0x00, 0x00, 0x00, 0x00, 0x00, 0x00, 0x00, 0xc0, 0x00, 0x00, 0x00, 0x00, 0x00, 0x00, 0x00,
			0x00, 0x00, 0x00, 0x00, 0xe0, 0x00, 0x00, 0x00, 0x00, 0x08, 0x00, 0x00, 0x18, 0x00, 0x00, 0x98,
			0x00, 0x00, 0x00, 0x00, 0x20, 0x00, 0x00, 0x00, 0x00, 0x00, 0x08, 0x00, 0x00, 0x00, 0x00, 0x00,
			0x00, 0x00, 0x00, 0x00, 0x00, 0x08, 0x00, 0x00, 0x00, 0x00, 0x00, 0x90, 0x00, 0x00, 0x00, 0x00,
			0x60, 0x00, 0x00, 0x10, 0x00, 0x00, 0x00, 0x00, 0x00, 0x00, 0x00, 0x00, 0x00, 0x00, 0xc0, 0x00,
			0x00, 0x00, 0x00, 0x00, 0x00, 0x00, 0x00, 0x00, 0x00, 0x00, 0x00, 0x00, 0x00, 0x00, 0x00, 0x00,
			0x00, 0x00, 0x00, 0x00, 0x88, 0x00, 0x00, 0x00, 0x00, 0x00, 0x40, 0x00, 0x00, 0x00, 0x00, 0x00,
			0x00, 0x00, 0x80, 0x00, 0x00, 0x81, 0x00, 0x00, 0x80, 0x00, 0x00, 0x00, 0x00, 0x00, 0x00, 0x00,
			0x84, 0x00, 0x00, 0x00, 0x00, 0x00, 0x00, 0x00, 0x38, 0x00, 0x00, 0x00, 0x00, 0x00, 0x00, 0x00,
			0x00, 0x00, 0x00, 0x00, 0x30, 0x00, 0x00, 0x00, 0x00, 0x88, 0x00, 0x00, 0x80, 0x00, 0x00, 0x80,
			0x00, 0x00, 0x00, 0x00, 0x30, 0x00, 0x00, 0x00, 0x00, 0x00, 0x82, 0x00, 0x00, 0x00, 0x00, 0x00,
			0x00, 0x00, 0x00, 0x00, 0x00, 0x88, 0x00, 0x00, 0x00, 0x00, 0x00, 0x40, 0x00, 0x00, 0x00, 0x00,
			0x30, 0x00, 0x00, 0x80, 0x00, 0x00, 0x00, 0x00, 0x00, 0x00, 0x00, 0x00, 0x00, 0x00, 0x1f, 0x00,
			0x00, 0x00, 0x00, 0x00, 0x00, 0x00, 0x00, 0x00, 0x00, 0x00, 0x00, 0x00, 0x20, 0x00, 0x00, 0x80,
			0x00, 0x00, 0x00, 0x00, 0x20, 0x00, 0x00, 0x00, 0x00, 0x00, 0x00, 0x00, 0x00, 0x00, 0x00, 0xc0,
			0x00, 0x00, 0x00, 0x00, 0x00, 0x20, 0x00, 0x00, 0x00, 0x00, 0x00, 0x00, 0x00, 0x40, 0x00, 0x00,
			0x00, 0x00, 0x00, 0x00, 0x00, 0x00, 0x80, 0x00, 0x00, 0x00, 0x00, 0x40, 0x00, 0x00, 0x00, 0x00,
			0x00, 0x00, 0x00, 0x00, 0x80, 0x00, 0x00, 0x00, 0x00, 0x00, 0x00, 0x00, 0x60, 0x00, 0x00, 0x00,
			0x00, 0x00, 0x00, 0x00, 0x00, 0x00, 0x00, 0x00, 0x00, 0x00, 0x00, 0x00, 0x00, 0x00, 0x00, 0x00,
			0x00, 0x00, 0x00, 0x00, 0x00, 0x00, 0x00, 0x00, 0x20, 0x00, 0x00, 0x40, 0x00, 0x00, 0x00, 0x00,
			0x80, 0x00, 0x00, 0x20, 0x00, 0x00, 0x00, 0x00, 0x00, 0x00, 0x00, 0x00, 0x00, 0x00, 0x00, 0x00,
			0x00, 0x00, 0x00, 0x00, 0x00, 0x00, 0x00, 0x00, 0x00, 0x00, 0x00, 0x00, 0x02, 0x00, 0x00, 0xc3,
			0x00, 0x00, 0x00, 0x00, 0x20, 0x00, 0x00, 0x00, 0x00, 0x00, 0x00, 0x00, 0x00, 0x00, 0x00, 0xc0,
			0x00, 0x00, 0x00, 0x00, 0x00, 0x04, 0x00, 0x00, 0x00, 0x00, 0x00, 0x00, 0x00, 0x00, 0x00, 0x00,
			0x00, 0x00, 0x00, 0x00, 0x00, 0x00, 0xc3, 0x00, 0xe3, 0x00, 0x00, 0x00, 0x00, 0x00, 0x00, 0x00,
			0x00, 0x00, 0x00, 0x00, 0xc3, 0x00, 0x00, 0x00, 0x00, 0x00, 0x00, 0x00, 0x00, 0x00, 0x00, 0x00,
			0x00, 0x00, 0xe3, 0x00, 0x00, 0x00, 0x00, 0x00, 0x00, 0x00, 0x00, 0x00, 0x00, 0x00, 0x00, 0x00,
			0x00, 0x00, 0x00, 0x00, 0x00, 0x00, 0x00, 0x00, 0x0c, 0x00, 0x00, 0x02, 0x00, 0x00, 0x00, 0x00,
			0xc1, 0x00, 0x00, 0x20, 0x00, 0x00, 0x00, 0x00, 0x00, 0x00, 0x00, 0x00, 0x7f, 0x00, 0x7f, 0x00};

char *DenumiriMeniu[ItemiMeniu] = { "Voltmetru digital", "Voltmetru analog", "Temperatura", "Surpriza" ,"Credits", "Istoric"};

/* USER CODE END 0 */

int main(void)
{

  /* MCU Configuration--------------------------------------------------------*/

  /* Reset of all peripherals, Initializes the Flash interface and the Systick. */
  HAL_Init();

  /* Configure the system clock */
  SystemClock_Config();

  /* Initialize all configured peripherals */
  MX_GPIO_Init();
  MX_TIM16_Init();
  MX_ADC_Init();
  MX_SPI1_Init();
  /* USER CODE BEGIN 2 */
	uint16_t adcValue = 0;
	double Voltage_mV = 0;
	double Voltage_V = 0;
	double voltageanalog= 0;
	//Start timer used for displaying a char on the bottom left corner each second
	HAL_TIM_Base_Start(&htim16);

	// initialize LCD
	st7565_init();
	st7565_backlight_enable();
	//HAL_Delay(500);

	/* Draw lines */
	/*for (uint16_t i = 0; i < 256; i += 4) //Line from point (0,0) to point ( i+4, 63 )
	{
		st7565_drawline(buffer, 0, 0, i, 63, 1);
		HAL_Delay(50);
		st7565_write_buffer(buffer);
	}*/
	//HAL_Delay(2000);
	st7565_clear_buffer(buffer);
	//HAL_Delay(500);

		uint8_t poza = 0;

  /* USER CODE END 2 */

  /* Infinite loop */
  /* USER CODE BEGIN WHILE */

	 uint8_t minim = 0;
	 uint8_t maxim= 5;

	 int currentValue = 1 - checkLCD();
	 int nextValue;
	 int buton = 0;
	 int8_t adcstate = 0;
	 int istoric[10];
	 uint8_t indexistoric=0;

	 int8_t indexmeniu = 0;
	 int8_t indexcase1 = 0;
	 uint8_t butonapasat = 0;
	// HAL_ADCEx_Calibration_Start(&hadc);

	while (1)
	{
		HAL_ADC_Stop(&hadc);
		HAL_ADC_Start(&hadc);
		nextValue = checkLCD();
		st7565_clear_buffer(buffer);

		if (nextValue == 0 && currentValue != nextValue)//dezactivare display si activare bec
		{
			st7565_clear_screen();
			st7565_backlight_disable();
			initA5GPIO();
			HAL_GPIO_WritePin(GPIOA, GPIO_PIN_5, 1);
		}

		if (nextValue == 1 && currentValue != nextValue) //dezactivare bec si reinitializare SPI
		{
			HAL_GPIO_WritePin(GPIOA, GPIO_PIN_5, 0);
			initA5SPI();
			MX_SPI1_Init();
			st7565_init();
			st7565_backlight_enable();
		}
		currentValue = nextValue;
		ADC_Select_CH0(1);

		HAL_ADC_Start(&hadc);
						HAL_ADC_PollForConversion(&hadc, HAL_MAX_DELAY);
						uint16_t joystickinpudt = HAL_ADC_GetValue(&hadc);
						ADC_Select_CH0(ADC_RANK_NONE);

		switch(indexmeniu)
		{

			case 0:
			{

				ADC_Select_CH0(1);
				HAL_ADC_Start(&hadc);
				HAL_ADC_PollForConversion(&hadc, HAL_MAX_DELAY);
				uint16_t joystickinput = HAL_ADC_GetValue(&hadc);

				for(uint8_t i = 0; i < ItemiMeniu; i++ )
					{
					st7565_drawstring(buffer, 12, i,DenumiriMeniu[i]);
					}
				st7565_drawstring(buffer, 113, indexcase1,"<-");
				st7565_drawstring(buffer, 0, indexcase1,"->");
				st7565_write_buffer(buffer);

				if(joystickinput>350 && joystickinput<630)
				{
					if(indexcase1==5)
						indexcase1 = -1;
					indexcase1++;
					st7565_drawstring(buffer, 113, indexcase1,"<-");
					st7565_drawstring(buffer, 0, indexcase1,"->");
					st7565_write_buffer(buffer);

				}
				if (joystickinput>100&&joystickinput<350)
					{//indexmeniu++;
						if(indexcase1 == 0)
							indexmeniu++;
						else if (indexcase1 == 1)
							indexmeniu+=2;
						else if (indexcase1 == 2)
							indexmeniu+=3;
						else if (indexcase1 == 3)
							indexmeniu+=4;
						else if (indexcase1 == 4)
							indexmeniu+=5;
						else if(indexcase1 == 5)
							indexmeniu+=6;

				}
				HAL_Delay(200);

				break;
			}
			case 1:	//digital
			{

				if((HAL_GPIO_ReadPin(GPIOC, GPIO_PIN_13) == 0 )&&(butonapasat == 1))
					{
					while (HAL_GPIO_ReadPin(GPIOC, GPIO_PIN_13) == 0 )
					{
					}
					butonapasat = 0;
					}

				else if ((HAL_GPIO_ReadPin(GPIOC, GPIO_PIN_13) == 0 )&&(butonapasat == 0))
				{
					while (HAL_GPIO_ReadPin(GPIOC, GPIO_PIN_13) == 0 )
					{
					}
					butonapasat = 1;
				}
				if(butonapasat == 0)
				{
				ADC_Select_CH0(ADC_RANK_NONE);
				ADC_Select_CH13(1);
				HAL_ADC_Start(&hadc);
				HAL_ADC_PollForConversion(&hadc, HAL_MAX_DELAY);

				adcValue = HAL_ADC_GetValue(&hadc);

				Voltage_mV = adcValue *3.22;
				Voltage_V = (Voltage_mV / 1000);
				if(indexistoric<7)
				{
					istoric[indexistoric]=adcValue;
					indexistoric++;
				}
				else
				{
					for(int cnt=0;cnt<6;cnt++)
					{
						istoric[cnt]=istoric[cnt+1];
					}
					istoric[6]=adcValue;
				}
				if (Voltage_V <= minim) poza = 0;
				else if (Voltage_V > maxim) poza = 7;
				else if (Voltage_V < 1) poza = 1;
				else if (Voltage_V < 2 && Voltage_V >= 1) poza = 2;
				else if (Voltage_V < 3 && Voltage_V >= 2) poza = 3;
				else if (Voltage_V < 4 && Voltage_V >= 3) poza = 4;
				else if (Voltage_V < 4.5 && Voltage_V >= 4) poza = 5;
				else if (Voltage_V <= 5 && Voltage_V >= 4.5) poza = 6;
				switch (poza)
					{
						case 0:
							{
								st7565_clear_screen();
								st7565_backlight_disable();
								break;
							}

						case 1:
							{
								st7565_drawbitmap(buffer, 0, 0, ptData, 128, 64, 1);
								st7565_write_buffer(buffer);
								break;
							}

						case 2:
							{
								st7565_drawbitmap(buffer, 0, 0, ptData1, 128, 64, 1);
								st7565_write_buffer(buffer);
								break;
							}

						case 3:
							{
								st7565_drawbitmap(buffer, 0, 0, ptData2, 128, 64, 1);
								st7565_write_buffer(buffer);
								break;
							}

						case 4:
							{
								st7565_drawbitmap(buffer, 0, 0, ptData3, 128, 64, 1);
								st7565_write_buffer(buffer);
								break;
							}

						case 5:
							{
								st7565_drawbitmap(buffer, 0, 0, ptData4, 128, 64, 1);
								st7565_write_buffer(buffer);
								break;
							}

						case 6:
							{
								st7565_drawbitmap(buffer, 0, 0, ptData5, 128, 64, 1);
								st7565_write_buffer(buffer);
								break;
							}

						case 7:
							{
								while (Voltage_V > maxim)
								{
									st7565_backlight_disable();
									HAL_Delay(2000);
									st7565_backlight_enable();
								}

								break;
							}

					}
				if(Voltage_V>minim)
							{
					//	st7565_backlight_enable();
							uint8_t* text = (unsigned char *)("Volti: ");
							//uint8_t v = (double)(Voltage_V);
							st7565_drawstring(buffer, 0, 0, text);
							char c[11]="";
							sprintf(c,"%.1f",Voltage_V);
							st7565_drawstring(buffer, 35, 0, c);
							text = (unsigned char *)("Milivolti: ");
							c[11]="";
							st7565_drawstring(buffer, 0, 1, text);
										sprintf(c,"%.1f",Voltage_mV);
										st7565_drawstring(buffer, 60, 1, c);
							}

						//	st7565_drawchar(buffer, 0, 7, 0x30 );

							/* Send buffer to LCD */
							st7565_write_buffer(buffer);

							HAL_Delay(500);
							//if(HAL_GPIO_ReadPin(GPIOC, 13) == 0);
							//ADC_Select_CH0();
				}
				else
				{
					ADC_Select_CH0(1);
					HAL_ADC_Start(&hadc);
					HAL_ADC_PollForConversion(&hadc, HAL_MAX_DELAY);
					uint16_t joystickinput = HAL_ADC_GetValue(&hadc);
					if (joystickinput>100&&joystickinput<350)
					{
						indexmeniu=0;
						butonapasat = 0;
						HAL_Delay(500);

						break;
					}

				}

				break;
			}
			case 2://analog
			{

				if((HAL_GPIO_ReadPin(GPIOC, GPIO_PIN_13) == 0 )&&(butonapasat == 1))
					{
					while (HAL_GPIO_ReadPin(GPIOC, GPIO_PIN_13) == 0 )
					{
					}
					butonapasat = 0;
					}

				else if ((HAL_GPIO_ReadPin(GPIOC, GPIO_PIN_13) == 0 )&&(butonapasat == 0))
				{
					while (HAL_GPIO_ReadPin(GPIOC, GPIO_PIN_13) == 0 )
					{
					}
					butonapasat = 1;
				}
				if(butonapasat == 0)
				{

				st7565_drawbitmap(buffer, 0, 0, pozanalog, 128, 64, 1);

				ADC_Select_CH0(ADC_RANK_NONE);
				ADC_Select_CH13(1);
				HAL_ADC_Start(&hadc);
				HAL_ADC_PollForConversion(&hadc, HAL_MAX_DELAY);
				adcValue = HAL_ADC_GetValue(&hadc);
				voltageanalog = (adcValue *3.22)/1000;

				if(voltageanalog<0.5)
					st7565_drawline(buffer, 64, 64, 15, 42, 1);//0
				else if (voltageanalog<1)
					st7565_drawline(buffer, 64, 64, 22, 37, 1);//0.5
				else if (voltageanalog<1.5)
					st7565_drawline(buffer, 64, 64, 30, 32, 1);//1
				else if (voltageanalog<2)
					st7565_drawline(buffer, 64, 64, 39, 27, 1);//1.5
				else if (voltageanalog<2.5)
					st7565_drawline(buffer, 64, 64, 49, 22, 1);//2
				else if (voltageanalog<3)
					st7565_drawline(buffer, 64, 64, 64, 22, 1);//2.5
				else if (voltageanalog<3.5)
					st7565_drawline(buffer, 64, 64, 79, 22, 1);//3
				else if (voltageanalog<4)
					st7565_drawline(buffer, 64, 64, 88, 27, 1);//3.5
				else if (voltageanalog<4.5)
					st7565_drawline(buffer, 64, 64, 97, 32, 1);//4
				else if (voltageanalog<5)
					st7565_drawline(buffer, 64, 64, 104, 37, 1);//4.5
				else if (voltageanalog<=5.5)
					st7565_drawline(buffer, 64, 64, 111, 42, 1);//5
				st7565_write_buffer(buffer);
								}
				else
				{
					ADC_Select_CH0(1);
					HAL_ADC_Start(&hadc);
					HAL_ADC_PollForConversion(&hadc, HAL_MAX_DELAY);
					uint16_t joystickinput = HAL_ADC_GetValue(&hadc);
					if (joystickinput>100&&joystickinput<350)
					{
						indexmeniu=0;
						butonapasat = 0;
						HAL_Delay(500);
						break;
					}
				}
				break;

			}
			case 3://temperatura
			{
				if((HAL_GPIO_ReadPin(GPIOC, GPIO_PIN_13) == 0 )&&(butonapasat == 1))
					{
					while (HAL_GPIO_ReadPin(GPIOC, GPIO_PIN_13) == 0 )
					{
					}
					butonapasat = 0;
					}

				else if ((HAL_GPIO_ReadPin(GPIOC, GPIO_PIN_13) == 0 )&&(butonapasat == 0))
				{
					while (HAL_GPIO_ReadPin(GPIOC, GPIO_PIN_13) == 0 )
					{
					}
					butonapasat = 1;
				}
				if(butonapasat == 0)
				{
				st7565_clear_buffer(buffer);
				st7565_drawbitmap(buffer, 0, 0, termometrupoza, 128, 64, 1);
				ADC_Select_CH0(ADC_RANK_NONE);
				ADC_Select_CH13(ADC_RANK_NONE);
				 ADC_Select_CHTemp(1);
				 HAL_ADC_Start(&hadc);
				 HAL_ADC_PollForConversion(&hadc, HAL_MAX_DELAY);
				// Temp = ((3.3*HAL_ADC_GetValue(&hadc)/1023 - V25)/Avg_Slope)+25;
				 Temp= (float)((HAL_ADC_GetValue(&hadc)*3300/1024 -500)/10-32)*5/9-10;
				// Temp = (HAL_ADC_GetValue(&hadc)*(3300/1024))*100;
				 uint8_t* text = (unsigned char *)("Temperatura: ");
				 st7565_drawstring(buffer, 0, 3, text);
				 char c[11]="";
				 sprintf(c,"%.1f",Temp);

				 st7565_drawstring(buffer, 70, 3, c);
				 if(Temp<25)
				 {
					 st7565_drawline(buffer, 115, 50, 115, 40, 255);
					 st7565_drawline(buffer, 114, 50, 114, 40, 255);
					 st7565_drawline(buffer, 116, 50, 116, 40, 255);
				 }
				 else if (Temp<30)
				 {
					st7565_drawline(buffer, 115, 50, 115, 30, 255);
					st7565_drawline(buffer, 114, 50, 114, 30, 255);
					st7565_drawline(buffer, 116, 50, 116, 30, 255);
				 }
				 else if (Temp<35)
				 {
					st7565_drawline(buffer, 115, 50, 115, 20, 255);
					st7565_drawline(buffer, 114, 50, 114, 20, 255);
					st7565_drawline(buffer, 116, 50, 116, 20, 255);
				 }
				 else if (Temp>=35)
				 {
					st7565_drawline(buffer, 115, 50, 115, 10, 255);
					st7565_drawline(buffer, 114, 50, 114, 10, 255);
					st7565_drawline(buffer, 116, 50, 116, 10, 255);
				 }
				 st7565_write_buffer(buffer);

				}
				else
				{
					ADC_Select_CH0(1);
					HAL_ADC_Start(&hadc);
					HAL_ADC_PollForConversion(&hadc, HAL_MAX_DELAY);
					uint16_t joystickinput = HAL_ADC_GetValue(&hadc);
					if (joystickinput>100&&joystickinput<350)
					{
						indexmeniu=0;
						butonapasat = 0;
						HAL_Delay(500);
						break;
					}
				}
				break;
			}
			case 4://minigame
			{
				if((HAL_GPIO_ReadPin(GPIOC, GPIO_PIN_13) == 0 )&&(butonapasat == 1))
					{
					while (HAL_GPIO_ReadPin(GPIOC, GPIO_PIN_13) == 0 )
					{
					}
					butonapasat = 0;
					}

				else if ((HAL_GPIO_ReadPin(GPIOC, GPIO_PIN_13) == 0 )&&(butonapasat == 0))
				{
					while (HAL_GPIO_ReadPin(GPIOC, GPIO_PIN_13) == 0 )
					{
					}
					butonapasat = 1;
				}
				if(butonapasat == 0)
				{
				st7565_drawfallingbitmap(buffer, pozafall, 128, 64);
				//st7565_drawstring(buffer, 0, 0, pozafall);
				}
				else
				{
					ADC_Select_CH0(1);
					HAL_ADC_Start(&hadc);
					HAL_ADC_PollForConversion(&hadc, HAL_MAX_DELAY);
					uint16_t joystickinput = HAL_ADC_GetValue(&hadc);
					if (joystickinput>100&&joystickinput<350)
					{
						indexmeniu=0;
						butonapasat = 0;
						HAL_Delay(500);
						break;
					}
				}
				break;
			}
			case 5://prezentare
			{
				if((HAL_GPIO_ReadPin(GPIOC, GPIO_PIN_13) == 0 )&&(butonapasat == 1))
					{
					while (HAL_GPIO_ReadPin(GPIOC, GPIO_PIN_13) == 0 )
					{
					}
					butonapasat = 0;
					}

				else if ((HAL_GPIO_ReadPin(GPIOC, GPIO_PIN_13) == 0 )&&(butonapasat == 0))
				{
					while (HAL_GPIO_ReadPin(GPIOC, GPIO_PIN_13) == 0 )
					{
					}
					butonapasat = 1;
				}
				if(butonapasat == 0)
				{
				int32_t text = (unsigned char *)("Sovaiala Alexandru     PREH WORKSHOP            2022 ");
				st7565_drawstring(buffer, 10, 2, text);
				st7565_write_buffer(buffer);
				}
				else
				{
					ADC_Select_CH0(1);
					HAL_ADC_Start(&hadc);
					HAL_ADC_PollForConversion(&hadc, HAL_MAX_DELAY);
					uint16_t joystickinput = HAL_ADC_GetValue(&hadc);
					if (joystickinput>100&&joystickinput<350)
					{
						indexmeniu=0;
						butonapasat = 0;
						HAL_Delay(500);
						break;
					}
				}

				break;
			}
			case 6://istoric
			{
				if((HAL_GPIO_ReadPin(GPIOC, GPIO_PIN_13) == 0 )&&(butonapasat == 1))
					{
					while (HAL_GPIO_ReadPin(GPIOC, GPIO_PIN_13) == 0 )
					{
					}
					butonapasat = 0;
					}

				else if ((HAL_GPIO_ReadPin(GPIOC, GPIO_PIN_13) == 0 )&&(butonapasat == 0))
				{
					while (HAL_GPIO_ReadPin(GPIOC, GPIO_PIN_13) == 0 )
					{
					}
					butonapasat = 1;
				}
				if(butonapasat == 0)
				{
				int32_t text = (unsigned char *)(" Volti      MiliV ");
				st7565_drawstring(buffer, 10, 0, text);

				for (int nr=0;nr<7;nr++)
				{
					char c[11]="";
					double voltage = istoric[nr]*3.3/1024;
					sprintf(c,"%.1f",voltage);
					char sirgol[11]="     ";
					strcat(c,sirgol);
					char c2[11]="";
					sprintf(c2,"%.3f",voltage*1000);
					strcat(c,c2);
					 st7565_drawstring(buffer, 20, nr+1, c);
				}

				 	for (int nr=0;nr<8;nr++)
				 	{
				 		st7565_drawrect(buffer, 0, nr*8, 64, 8, 1);
				 		st7565_drawrect(buffer, 64,nr*8, 64, 8, 1);
				 	}

				st7565_write_buffer(buffer);
				}
				else
				{
					ADC_Select_CH0(1);
					HAL_ADC_Start(&hadc);
					HAL_ADC_PollForConversion(&hadc, HAL_MAX_DELAY);
					uint16_t joystickinput = HAL_ADC_GetValue(&hadc);
					if (joystickinput>100&&joystickinput<350)
					{
						indexmeniu=0;
						butonapasat = 0;
						HAL_Delay(500);
						break;
					}
				}

				break;
			}
		}

		/* Check if timer had overflow */
		if(__HAL_TIM_GET_FLAG(&htim16,TIM_FLAG_CC1) != 0)
		{
			/* Clear overflow flag */
			__HAL_TIM_CLEAR_FLAG(&htim16,TIM_FLAG_CC1);

			/* Prepare buffer with string & bottom left char */

		}

    /* USER CODE END WHILE */

	}
}

void SystemClock_Config(void)
{
  RCC_OscInitTypeDef RCC_OscInitStruct = {0};
  RCC_ClkInitTypeDef RCC_ClkInitStruct = {0};

  /** Initializes the RCC Oscillators according to the specified parameters
  * in the RCC_OscInitTypeDef structure.
  */
  RCC_OscInitStruct.OscillatorType = RCC_OSCILLATORTYPE_HSI14|RCC_OSCILLATORTYPE_HSI48;
  RCC_OscInitStruct.HSI48State = RCC_HSI48_ON;
  RCC_OscInitStruct.HSI14State = RCC_HSI14_ON;
  RCC_OscInitStruct.HSI14CalibrationValue = 16;
  RCC_OscInitStruct.PLL.PLLState = RCC_PLL_NONE;
  if (HAL_RCC_OscConfig(&RCC_OscInitStruct) != HAL_OK)
  {
    Error_Handler();
  }
  /** Initializes the CPU, AHB and APB buses clocks
  */
  RCC_ClkInitStruct.ClockType = RCC_CLOCKTYPE_HCLK|RCC_CLOCKTYPE_SYSCLK
                              |RCC_CLOCKTYPE_PCLK1;
  RCC_ClkInitStruct.SYSCLKSource = RCC_SYSCLKSOURCE_HSI48;
  RCC_ClkInitStruct.AHBCLKDivider = RCC_SYSCLK_DIV1;
  RCC_ClkInitStruct.APB1CLKDivider = RCC_HCLK_DIV1;

  if (HAL_RCC_ClockConfig(&RCC_ClkInitStruct, FLASH_LATENCY_1) != HAL_OK)
  {
    Error_Handler();
  }
}

static void MX_ADC_Init(void)
{

  ADC_ChannelConfTypeDef sConfig = {0};

  /** Configure the global features of the ADC (Clock, Resolution, Data Alignment and number of conversion)
  */
  hadc.Instance = ADC1;
  hadc.Init.ClockPrescaler = ADC_CLOCK_ASYNC_DIV1;
  hadc.Init.Resolution = ADC_RESOLUTION_10B;
  hadc.Init.DataAlign = ADC_DATAALIGN_RIGHT;
  hadc.Init.ScanConvMode = ADC_SCAN_DIRECTION_FORWARD;
  hadc.Init.EOCSelection = ADC_EOC_SINGLE_CONV;
  hadc.Init.LowPowerAutoWait = DISABLE;
  hadc.Init.LowPowerAutoPowerOff = DISABLE;
  hadc.Init.ContinuousConvMode = DISABLE;
  hadc.Init.DiscontinuousConvMode = DISABLE;
  hadc.Init.ExternalTrigConv = ADC_SOFTWARE_START;
  hadc.Init.ExternalTrigConvEdge = ADC_EXTERNALTRIGCONVEDGE_NONE;
  hadc.Init.DMAContinuousRequests = DISABLE;
  hadc.Init.Overrun = ADC_OVR_DATA_PRESERVED;
  if (HAL_ADC_Init(&hadc) != HAL_OK)
  {
    Error_Handler();
  }
  /** Configure for the selected ADC regular channel to be converted.
  */
//  sConfig.Channel = ADC_CHANNEL_0;
//  sConfig.Rank = ADC_RANK_CHANNEL_NUMBER;
//  sConfig.SamplingTime = ADC_SAMPLETIME_1CYCLE_5;
//  if (HAL_ADC_ConfigChannel(&hadc, &sConfig) != HAL_OK)
//  {
//    Error_Handler();
//  }
//  /** Configure for the selected ADC regular channel to be converted.
//  */
//  sConfig.Channel = ADC_CHANNEL_13;
//  if (HAL_ADC_ConfigChannel(&hadc, &sConfig) != HAL_OK)
//  {
//    Error_Handler();
//  }
//  /** Configure for the selected ADC regular channel to be converted.
//  */
//  sConfig.Channel = ADC_CHANNEL_TEMPSENSOR;
//  if (HAL_ADC_ConfigChannel(&hadc, &sConfig) != HAL_OK)
//  {
//    Error_Handler();
//  }
//  /** Configure for the selected ADC regular channel to be converted.
//  */
//  sConfig.Channel = ADC_CHANNEL_VBAT;
//  if (HAL_ADC_ConfigChannel(&hadc, &sConfig) != HAL_OK)
//  {
//    Error_Handler();
//  }
//  /* USER CODE BEGIN ADC_Init 2 */
//
//  /* USER CODE END ADC_Init 2 */

}

void ADC_Select_CH13 (int rang)
  {
    	ADC_ChannelConfTypeDef sConfig = {0};
  	  /** Configure for the selected ADC regular channel its corresponding rank in the sequencer and its sample time.
  	  */
  	  sConfig.Channel = ADC_CHANNEL_13;
  	  sConfig.Rank = rang;
  	  sConfig.SamplingTime = ADC_SAMPLETIME_1CYCLE_5;
  	  if (HAL_ADC_ConfigChannel(&hadc, &sConfig) != HAL_OK)
  	  {
  	    Error_Handler();
  	  }
  }
void ADC_Disable_CH13(void)
{
	ADC_ChannelConfTypeDef sConfig = {0};

	sConfig.Channel = ADC_CHANNEL_13;
	sConfig.Rank= ADC_RANK_NONE;
	sConfig.SamplingTime = ADC_SAMPLETIME_1CYCLE_5;
}

  void ADC_Select_CH0 (int rang)
   {
   	ADC_ChannelConfTypeDef sConfig = {0};
   	  /** Configure for the selected ADC regular channel its corresponding rank in the sequencer and its sample time.
   	  */
   	  sConfig.Channel = ADC_CHANNEL_0;
   	  sConfig.Rank = rang;
   	  sConfig.SamplingTime = ADC_SAMPLETIME_1CYCLE_5;
   	  if (HAL_ADC_ConfigChannel(&hadc, &sConfig) != HAL_OK)
   	  {
   	    Error_Handler();
   	  }
   }
  void ADC_Disable_CH0(void)
  {
  	ADC_ChannelConfTypeDef sConfig = {0};

  	sConfig.Channel = ADC_CHANNEL_0;
  	sConfig.Rank= ADC_RANK_NONE;
  	sConfig.SamplingTime = ADC_SAMPLETIME_1CYCLE_5;
  }
  void ADC_Select_CHTemp (int rang)
  {
  	ADC_ChannelConfTypeDef sConfig = {0};
  	  /** Configure for the selected ADC regular channel its corresponding rank in the sequencer and its sample time.
  	  */
  	  sConfig.Channel = ADC_CHANNEL_TEMPSENSOR;
  	  sConfig.Rank = rang;
  	  sConfig.SamplingTime = ADC_SAMPLETIME_1CYCLE_5;
  	  if (HAL_ADC_ConfigChannel(&hadc, &sConfig) != HAL_OK)
  	  {
  	    Error_Handler();
  	  }
  }
  void ADC_Disable_CHTemp(void)
  {
  	ADC_ChannelConfTypeDef sConfig = {0};

  	sConfig.Channel = ADC_CHANNEL_TEMPSENSOR;
  	sConfig.Rank= ADC_RANK_NONE;
  	sConfig.SamplingTime = ADC_SAMPLETIME_1CYCLE_5;
  }

static void MX_SPI1_Init(void)
{

  /* SPI1 parameter configuration*/
  hspi1.Instance = SPI1;
  hspi1.Init.Mode = SPI_MODE_MASTER;
  hspi1.Init.Direction = SPI_DIRECTION_2LINES;
  hspi1.Init.DataSize = SPI_DATASIZE_8BIT;
  hspi1.Init.CLKPolarity = SPI_POLARITY_LOW;
  hspi1.Init.CLKPhase = SPI_PHASE_1EDGE;
  hspi1.Init.NSS = SPI_NSS_SOFT;
  hspi1.Init.BaudRatePrescaler = SPI_BAUDRATEPRESCALER_128;
  hspi1.Init.FirstBit = SPI_FIRSTBIT_MSB;
  hspi1.Init.TIMode = SPI_TIMODE_DISABLE;
  hspi1.Init.CRCCalculation = SPI_CRCCALCULATION_DISABLE;
  hspi1.Init.CRCPolynomial = 7;
  hspi1.Init.CRCLength = SPI_CRC_LENGTH_DATASIZE;
  hspi1.Init.NSSPMode = SPI_NSS_PULSE_ENABLE;
  if (HAL_SPI_Init(&hspi1) != HAL_OK)
  {
    Error_Handler();
  }

}

static void MX_TIM16_Init(void)
{

  htim16.Instance = TIM16;
  htim16.Init.Prescaler = 4800-1;
  htim16.Init.CounterMode = TIM_COUNTERMODE_UP;
  htim16.Init.Period = 10000;
  htim16.Init.ClockDivision = TIM_CLOCKDIVISION_DIV1;
  htim16.Init.RepetitionCounter = 0;
  htim16.Init.AutoReloadPreload = TIM_AUTORELOAD_PRELOAD_DISABLE;
  if (HAL_TIM_Base_Init(&htim16) != HAL_OK)
  {
    Error_Handler();
  }

}

static void MX_GPIO_Init(void)
{
  GPIO_InitTypeDef GPIO_InitStruct = {0};

  /* GPIO Ports Clock Enable */
  __HAL_RCC_GPIOC_CLK_ENABLE();
  __HAL_RCC_GPIOF_CLK_ENABLE();
  __HAL_RCC_GPIOA_CLK_ENABLE();
  __HAL_RCC_GPIOB_CLK_ENABLE();

  /*Configure GPIO pin Output Level */
  HAL_GPIO_WritePin(SPICD_GPIO_Port, SPICD_Pin, GPIO_PIN_SET);

  /*Configure GPIO pin Output Level */
  HAL_GPIO_WritePin(GPIOA, BL_Pin|SPIRST_Pin, GPIO_PIN_RESET);

  /*Configure GPIO pin Output Level */
  HAL_GPIO_WritePin(GPIOB, GPIO_PIN_3|SPICS_Pin, GPIO_PIN_RESET);

  /*Configure GPIO pin : PC13 */
  GPIO_InitStruct.Pin = GPIO_PIN_13;
  GPIO_InitStruct.Mode = GPIO_MODE_INPUT;
  GPIO_InitStruct.Pull = GPIO_NOPULL;
  HAL_GPIO_Init(GPIOC, &GPIO_InitStruct);

  /*Configure GPIO pin : SPICD_Pin */
  GPIO_InitStruct.Pin = SPICD_Pin;
  GPIO_InitStruct.Mode = GPIO_MODE_OUTPUT_PP;
  GPIO_InitStruct.Pull = GPIO_NOPULL;
  GPIO_InitStruct.Speed = GPIO_SPEED_FREQ_LOW;
  HAL_GPIO_Init(SPICD_GPIO_Port, &GPIO_InitStruct);

  /*Configure GPIO pins : BL_Pin SPIRST_Pin */
  GPIO_InitStruct.Pin = BL_Pin|SPIRST_Pin;
  GPIO_InitStruct.Mode = GPIO_MODE_OUTPUT_PP;
  GPIO_InitStruct.Pull = GPIO_NOPULL;
  GPIO_InitStruct.Speed = GPIO_SPEED_FREQ_LOW;
  HAL_GPIO_Init(GPIOA, &GPIO_InitStruct);

  /*Configure GPIO pins : PB3 SPICS_Pin */
  GPIO_InitStruct.Pin = GPIO_PIN_3|SPICS_Pin;
  GPIO_InitStruct.Mode = GPIO_MODE_OUTPUT_PP;
  GPIO_InitStruct.Pull = GPIO_NOPULL;
  GPIO_InitStruct.Speed = GPIO_SPEED_FREQ_LOW;
  HAL_GPIO_Init(GPIOB, &GPIO_InitStruct);

  /*Configure GPIO pin : PB5 */
  GPIO_InitStruct.Pin = GPIO_PIN_5;
  GPIO_InitStruct.Mode = GPIO_MODE_INPUT;
  GPIO_InitStruct.Pull = GPIO_NOPULL;
  HAL_GPIO_Init(GPIOB, &GPIO_InitStruct);

}

/* USER CODE BEGIN 4 */
int checkLCD() {
	if (HAL_GPIO_ReadPin(GPIOB, GPIO_PIN_5) == 0) return 1;
	else return 0;
}

void initA5GPIO() {
	GPIO_InitTypeDef GPIO_InitStruct = {0};

	GPIO_InitStruct.Pin = GPIO_PIN_5;
	GPIO_InitStruct.Mode = GPIO_MODE_OUTPUT_PP;
	GPIO_InitStruct.Pull = GPIO_NOPULL;
	GPIO_InitStruct.Speed = GPIO_SPEED_FREQ_LOW;
	HAL_GPIO_Init(GPIOA, &GPIO_InitStruct);
}

void initA5SPI() {
	GPIO_InitTypeDef GPIO_InitStruct = {0};

	GPIO_InitStruct.Pin = GPIO_PIN_5;
	GPIO_InitStruct.Mode = GPIO_MODE_AF_PP;
	GPIO_InitStruct.Pull = GPIO_NOPULL;
	GPIO_InitStruct.Speed = GPIO_SPEED_FREQ_LOW;
	HAL_GPIO_Init(GPIOA, &GPIO_InitStruct);
}
/* USER CODE END 4 */

void Error_Handler(void)
{
	__disable_irq();
	while (1)
	{
	}
}
